AUTOSAR XML (schema 4-2-2)
package /STELLANTIS/EPT/ASWCs
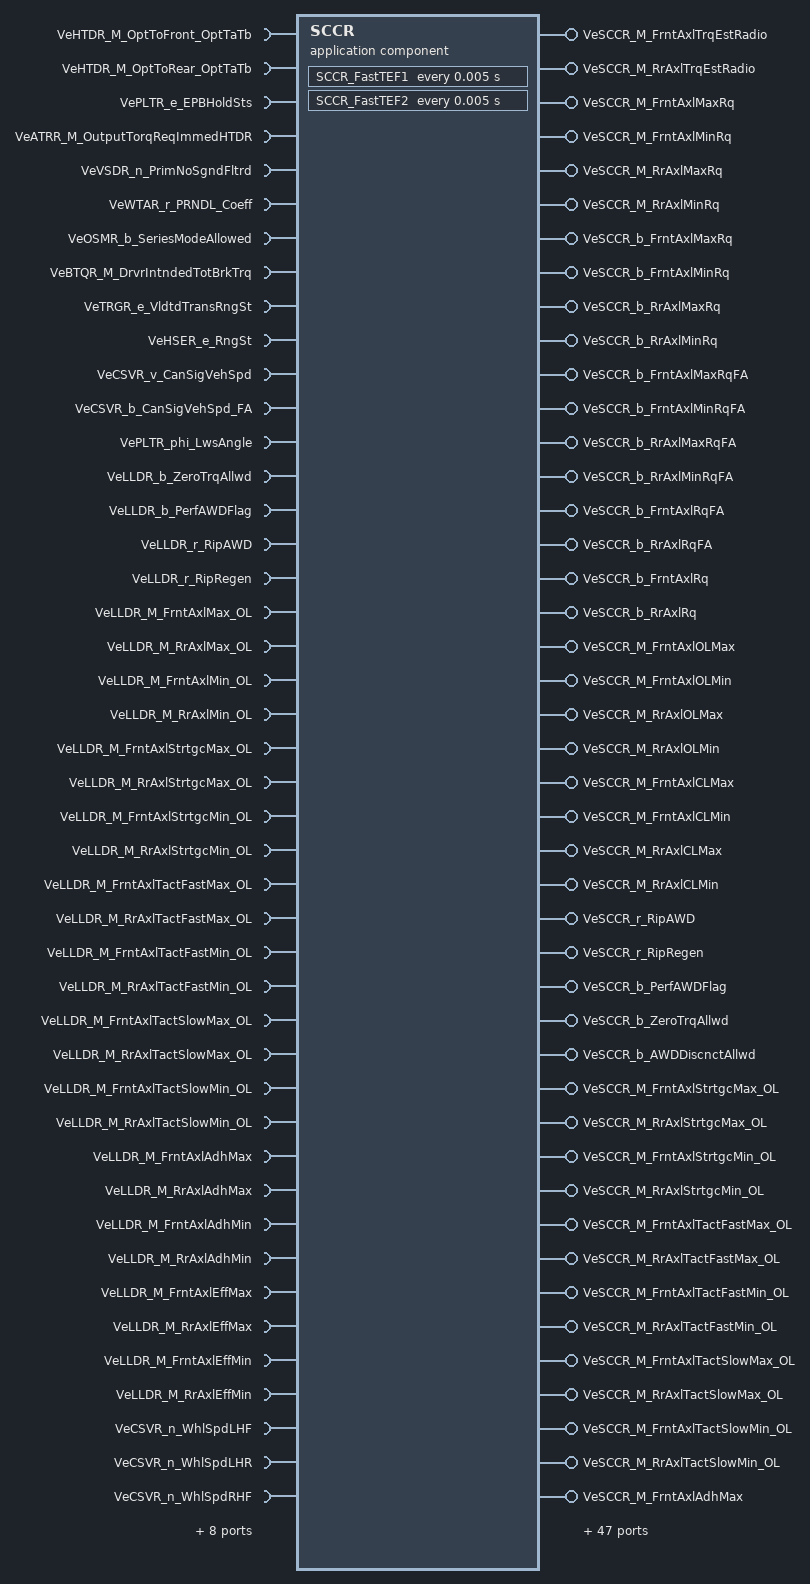
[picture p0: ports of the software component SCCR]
  application sw component type SCCR
    52 x require port:
      VeHTDR_M_OptToFront_OptTaTb: variation-point={short-label=vpVeHTDR_M_OptToFront_OptTaTb, sw-syscond=1}, nonqueued-receiver-com-spec{data-element=Value, init-value=0}, required-interface=VeHTDR_M_OptToFront_OptTaTb
      VeHTDR_M_OptToRear_OptTaTb: variation-point={short-label=vpVeHTDR_M_OptToRear_OptTaTb, sw-syscond=1}, nonqueued-receiver-com-spec{data-element=Value, init-value=0}, required-interface=VeHTDR_M_OptToRear_OptTaTb
      VePLTR_e_EPBHoldSts: variation-point={short-label=vpVePLTR_e_EPBHoldSts, sw-syscond=1}, nonqueued-receiver-com-spec{data-element=Value, init-value=CePLTR_e_EPBHoldSts_REL}, required-interface=VePLTR_e_EPBHoldSts
      VeATRR_M_OutputTorqReqImmedHTDR: variation-point={short-label=vpVeATRR_M_OutputTorqReqImmedHTDR, sw-syscond=1}, nonqueued-receiver-com-spec{data-element=Value, init-value=0}, required-interface=VeATRR_M_OutputTorqReqImmedHTDR
      VeVSDR_n_PrimNoSgndFltrd: variation-point={short-label=vpVeVSDR_n_PrimNoSgndFltrd, sw-syscond=1}, nonqueued-receiver-com-spec{data-element=Value, init-value=0}, required-interface=VeVSDR_n_PrimNoSgndFltrd
      VeWTAR_r_PRNDL_Coeff: variation-point={short-label=vpVeWTAR_r_PRNDL_Coeff, sw-syscond=1}, nonqueued-receiver-com-spec{data-element=Value, init-value=0}, required-interface=VeWTAR_r_PRNDL_Coeff
      VeOSMR_b_SeriesModeAllowed: variation-point={short-label=vpVeOSMR_b_SeriesModeAllowed, sw-syscond=1}, nonqueued-receiver-com-spec{data-element=Value, init-value=0}, required-interface=VeOSMR_b_SeriesModeAllowed
      VeBTQR_M_DrvrIntndedTotBrkTrq: variation-point={short-label=vpVeBTQR_M_DrvrIntndedTotBrkTrq, sw-syscond=1}, nonqueued-receiver-com-spec{data-element=Value, init-value=0}, required-interface=VeBTQR_M_DrvrIntndedTotBrkTrq
      VeTRGR_e_VldtdTransRngSt: variation-point={short-label=vpVeTRGR_e_VldtdTransRngSt, sw-syscond=1}, nonqueued-receiver-com-spec{data-element=Value, init-value=CeTRGR_e_NoSelectionAvailable}, required-interface=VeTRGR_e_VldtdTransRngSt
      VeHSER_e_RngSt: variation-point={short-label=vpVeHSER_e_RngSt, sw-syscond=1}, nonqueued-receiver-com-spec{data-element=Value, init-value=CeHSER_e_Init}, required-interface=VeHSER_e_RngSt
      VeCSVR_v_CanSigVehSpd: variation-point={short-label=vpVeCSVR_v_CanSigVehSpd, sw-syscond=1}, nonqueued-receiver-com-spec{data-element=Value, init-value=0}, required-interface=VeCSVR_v_CanSigVehSpd
      VeCSVR_b_CanSigVehSpd_FA: variation-point={short-label=vpVeCSVR_b_CanSigVehSpd_FA, sw-syscond=1}, nonqueued-receiver-com-spec{data-element=Value, init-value=0}, required-interface=VeCSVR_b_CanSigVehSpd_FA
      VePLTR_phi_LwsAngle: variation-point={short-label=vpVePLTR_phi_LwsAngle, sw-syscond=1}, nonqueued-receiver-com-spec{data-element=Value, init-value=0}, required-interface=VePLTR_phi_LwsAngle
      VeLLDR_b_ZeroTrqAllwd: variation-point={short-label=vpVeLLDR_b_ZeroTrqAllwd, sw-syscond=1}, nonqueued-receiver-com-spec{data-element=Value, init-value=0}, required-interface=VeLLDR_b_ZeroTrqAllwd
      VeLLDR_b_PerfAWDFlag: variation-point={short-label=vpVeLLDR_b_PerfAWDFlag, sw-syscond=1}, nonqueued-receiver-com-spec{data-element=Value, init-value=0}, required-interface=VeLLDR_b_PerfAWDFlag
      VeLLDR_r_RipAWD: variation-point={short-label=vpVeLLDR_r_RipAWD, sw-syscond=1}, nonqueued-receiver-com-spec{data-element=Value, init-value=0}, required-interface=VeLLDR_r_RipAWD
      VeLLDR_r_RipRegen: variation-point={short-label=vpVeLLDR_r_RipRegen, sw-syscond=1}, nonqueued-receiver-com-spec{data-element=Value, init-value=0}, required-interface=VeLLDR_r_RipRegen
      VeLLDR_M_FrntAxlMax_OL: variation-point={short-label=vpVeLLDR_M_FrntAxlMax_OL, sw-syscond=1}, nonqueued-receiver-com-spec{data-element=Value, init-value=0}, required-interface=VeLLDR_M_FrntAxlMax_OL
      VeLLDR_M_RrAxlMax_OL: variation-point={short-label=vpVeLLDR_M_RrAxlMax_OL, sw-syscond=1}, nonqueued-receiver-com-spec{data-element=Value, init-value=0}, required-interface=VeLLDR_M_RrAxlMax_OL
      VeLLDR_M_FrntAxlMin_OL: variation-point={short-label=vpVeLLDR_M_FrntAxlMin_OL, sw-syscond=1}, nonqueued-receiver-com-spec{data-element=Value, init-value=0}, required-interface=VeLLDR_M_FrntAxlMin_OL
      VeLLDR_M_RrAxlMin_OL: variation-point={short-label=vpVeLLDR_M_RrAxlMin_OL, sw-syscond=1}, nonqueued-receiver-com-spec{data-element=Value, init-value=0}, required-interface=VeLLDR_M_RrAxlMin_OL
      VeLLDR_M_FrntAxlStrtgcMax_OL: variation-point={short-label=vpVeLLDR_M_FrntAxlStrtgcMax_OL, sw-syscond=1}, nonqueued-receiver-com-spec{data-element=Value, init-value=0}, required-interface=VeLLDR_M_FrntAxlStrtgcMax_OL
      VeLLDR_M_RrAxlStrtgcMax_OL: variation-point={short-label=vpVeLLDR_M_RrAxlStrtgcMax_OL, sw-syscond=1}, nonqueued-receiver-com-spec{data-element=Value, init-value=0}, required-interface=VeLLDR_M_RrAxlStrtgcMax_OL
      VeLLDR_M_FrntAxlStrtgcMin_OL: variation-point={short-label=vpVeLLDR_M_FrntAxlStrtgcMin_OL, sw-syscond=1}, nonqueued-receiver-com-spec{data-element=Value, init-value=0}, required-interface=VeLLDR_M_FrntAxlStrtgcMin_OL
      VeLLDR_M_RrAxlStrtgcMin_OL: variation-point={short-label=vpVeLLDR_M_RrAxlStrtgcMin_OL, sw-syscond=1}, nonqueued-receiver-com-spec{data-element=Value, init-value=0}, required-interface=VeLLDR_M_RrAxlStrtgcMin_OL
      VeLLDR_M_FrntAxlTactFastMax_OL: variation-point={short-label=vpVeLLDR_M_FrntAxlTactFastMax_OL, sw-syscond=1}, nonqueued-receiver-com-spec{data-element=Value, init-value=0}, required-interface=VeLLDR_M_FrntAxlTactFastMax_OL
      VeLLDR_M_RrAxlTactFastMax_OL: variation-point={short-label=vpVeLLDR_M_RrAxlTactFastMax_OL, sw-syscond=1}, nonqueued-receiver-com-spec{data-element=Value, init-value=0}, required-interface=VeLLDR_M_RrAxlTactFastMax_OL
      VeLLDR_M_FrntAxlTactFastMin_OL: variation-point={short-label=vpVeLLDR_M_FrntAxlTactFastMin_OL, sw-syscond=1}, nonqueued-receiver-com-spec{data-element=Value, init-value=0}, required-interface=VeLLDR_M_FrntAxlTactFastMin_OL
      VeLLDR_M_RrAxlTactFastMin_OL: variation-point={short-label=vpVeLLDR_M_RrAxlTactFastMin_OL, sw-syscond=1}, nonqueued-receiver-com-spec{data-element=Value, init-value=0}, required-interface=VeLLDR_M_RrAxlTactFastMin_OL
      VeLLDR_M_FrntAxlTactSlowMax_OL: variation-point={short-label=vpVeLLDR_M_FrntAxlTactSlowMax_OL, sw-syscond=1}, nonqueued-receiver-com-spec{data-element=Value, init-value=0}, required-interface=VeLLDR_M_FrntAxlTactSlowMax_OL
      VeLLDR_M_RrAxlTactSlowMax_OL: variation-point={short-label=vpVeLLDR_M_RrAxlTactSlowMax_OL, sw-syscond=1}, nonqueued-receiver-com-spec{data-element=Value, init-value=0}, required-interface=VeLLDR_M_RrAxlTactSlowMax_OL
      VeLLDR_M_FrntAxlTactSlowMin_OL: variation-point={short-label=vpVeLLDR_M_FrntAxlTactSlowMin_OL, sw-syscond=1}, nonqueued-receiver-com-spec{data-element=Value, init-value=0}, required-interface=VeLLDR_M_FrntAxlTactSlowMin_OL
      VeLLDR_M_RrAxlTactSlowMin_OL: variation-point={short-label=vpVeLLDR_M_RrAxlTactSlowMin_OL, sw-syscond=1}, nonqueued-receiver-com-spec{data-element=Value, init-value=0}, required-interface=VeLLDR_M_RrAxlTactSlowMin_OL
      VeLLDR_M_FrntAxlAdhMax: variation-point={short-label=vpVeLLDR_M_FrntAxlAdhMax, sw-syscond=1}, nonqueued-receiver-com-spec{data-element=Value, init-value=0}, required-interface=VeLLDR_M_FrntAxlAdhMax
      VeLLDR_M_RrAxlAdhMax: variation-point={short-label=vpVeLLDR_M_RrAxlAdhMax, sw-syscond=1}, nonqueued-receiver-com-spec{data-element=Value, init-value=0}, required-interface=VeLLDR_M_RrAxlAdhMax
      VeLLDR_M_FrntAxlAdhMin: variation-point={short-label=vpVeLLDR_M_FrntAxlAdhMin, sw-syscond=1}, nonqueued-receiver-com-spec{data-element=Value, init-value=0}, required-interface=VeLLDR_M_FrntAxlAdhMin
      VeLLDR_M_RrAxlAdhMin: variation-point={short-label=vpVeLLDR_M_RrAxlAdhMin, sw-syscond=1}, nonqueued-receiver-com-spec{data-element=Value, init-value=0}, required-interface=VeLLDR_M_RrAxlAdhMin
      VeLLDR_M_FrntAxlEffMax: variation-point={short-label=vpVeLLDR_M_FrntAxlEffMax, sw-syscond=1}, nonqueued-receiver-com-spec{data-element=Value, init-value=0}, required-interface=VeLLDR_M_FrntAxlEffMax
      VeLLDR_M_RrAxlEffMax: variation-point={short-label=vpVeLLDR_M_RrAxlEffMax, sw-syscond=1}, nonqueued-receiver-com-spec{data-element=Value, init-value=0}, required-interface=VeLLDR_M_RrAxlEffMax
      VeLLDR_M_FrntAxlEffMin: variation-point={short-label=vpVeLLDR_M_FrntAxlEffMin, sw-syscond=1}, nonqueued-receiver-com-spec{data-element=Value, init-value=0}, required-interface=VeLLDR_M_FrntAxlEffMin
      VeLLDR_M_RrAxlEffMin: variation-point={short-label=vpVeLLDR_M_RrAxlEffMin, sw-syscond=1}, nonqueued-receiver-com-spec{data-element=Value, init-value=0}, required-interface=VeLLDR_M_RrAxlEffMin
      VeCSVR_n_WhlSpdLHF: variation-point={short-label=vpVeCSVR_n_WhlSpdLHF, sw-syscond=1}, nonqueued-receiver-com-spec{data-element=Value, init-value=0}, required-interface=VeCSVR_n_WhlSpdLHF
      VeCSVR_n_WhlSpdLHR: variation-point={short-label=vpVeCSVR_n_WhlSpdLHR, sw-syscond=1}, nonqueued-receiver-com-spec{data-element=Value, init-value=0}, required-interface=VeCSVR_n_WhlSpdLHR
      VeCSVR_n_WhlSpdRHF: variation-point={short-label=vpVeCSVR_n_WhlSpdRHF, sw-syscond=1}, nonqueued-receiver-com-spec{data-element=Value, init-value=0}, required-interface=VeCSVR_n_WhlSpdRHF
      VeCSVR_n_WhlSpdRHR: variation-point={short-label=vpVeCSVR_n_WhlSpdRHR, sw-syscond=1}, nonqueued-receiver-com-spec{data-element=Value, init-value=0}, required-interface=VeCSVR_n_WhlSpdRHR
      VeCSVR_b_WhlSpdLHF_FA: variation-point={short-label=vpVeCSVR_b_WhlSpdLHF_FA, sw-syscond=1}, nonqueued-receiver-com-spec{data-element=Value, init-value=0}, required-interface=VeCSVR_b_WhlSpdLHF_FA
      VeCSVR_b_WhlSpdLHR_FA: variation-point={short-label=vpVeCSVR_b_WhlSpdLHR_FA, sw-syscond=1}, nonqueued-receiver-com-spec{data-element=Value, init-value=0}, required-interface=VeCSVR_b_WhlSpdLHR_FA
      VeCSVR_b_WhlSpdRHF_FA: variation-point={short-label=vpVeCSVR_b_WhlSpdRHF_FA, sw-syscond=1}, nonqueued-receiver-com-spec{data-element=Value, init-value=0}, required-interface=VeCSVR_b_WhlSpdRHF_FA
      VeCSVR_b_WhlSpdRHR_FA: variation-point={short-label=vpVeCSVR_b_WhlSpdRHR_FA, sw-syscond=1}, nonqueued-receiver-com-spec{data-element=Value, init-value=0}, required-interface=VeCSVR_b_WhlSpdRHR_FA
      VeFWDR_M_FricTrqClutch: variation-point={short-label=vpVeFWDR_M_FricTrqClutch, sw-syscond=1}, nonqueued-receiver-com-spec{data-element=Value, init-value=0}, required-interface=VeFWDR_M_FricTrqClutch
      VeAXLR_M_OutTorqReqModHH_Axle: variation-point={short-label=vpVeAXLR_M_OutTorqReqModHH_Axle, sw-syscond=1}, nonqueued-receiver-com-spec{data-element=Value, init-value=0}, required-interface=VeAXLR_M_OutTorqReqModHH_Axle
      VeSRAR_e_LoCHCP_BSM_CANC: variation-point={short-label=vpVeSRAR_e_LoCHCP_BSM_CANC, sw-syscond=1}, nonqueued-receiver-com-spec{data-element=Value, init-value=CeSRAR_e_NoFaultHCPBSM_C1}, required-interface=VeSRAR_e_LoCHCP_BSM_CANC
    91 x provide port:
      VeSCCR_M_FrntAxlTrqEstRadio: nonqueued-sender-com-spec{data-element=Value, init-value=0}, provided-interface=VeSCCR_M_FrntAxlTrqEstRadio
      VeSCCR_M_RrAxlTrqEstRadio: nonqueued-sender-com-spec{data-element=Value, init-value=0}, provided-interface=VeSCCR_M_RrAxlTrqEstRadio
      VeSCCR_M_FrntAxlMaxRq: nonqueued-sender-com-spec{data-element=Value, init-value=0}, provided-interface=VeSCCR_M_FrntAxlMaxRq
      VeSCCR_M_FrntAxlMinRq: nonqueued-sender-com-spec{data-element=Value, init-value=0}, provided-interface=VeSCCR_M_FrntAxlMinRq
      VeSCCR_M_RrAxlMaxRq: nonqueued-sender-com-spec{data-element=Value, init-value=0}, provided-interface=VeSCCR_M_RrAxlMaxRq
      VeSCCR_M_RrAxlMinRq: nonqueued-sender-com-spec{data-element=Value, init-value=0}, provided-interface=VeSCCR_M_RrAxlMinRq
      VeSCCR_b_FrntAxlMaxRq: nonqueued-sender-com-spec{data-element=Value, init-value=0}, provided-interface=VeSCCR_b_FrntAxlMaxRq
      VeSCCR_b_FrntAxlMinRq: nonqueued-sender-com-spec{data-element=Value, init-value=0}, provided-interface=VeSCCR_b_FrntAxlMinRq
      VeSCCR_b_RrAxlMaxRq: nonqueued-sender-com-spec{data-element=Value, init-value=0}, provided-interface=VeSCCR_b_RrAxlMaxRq
      VeSCCR_b_RrAxlMinRq: nonqueued-sender-com-spec{data-element=Value, init-value=0}, provided-interface=VeSCCR_b_RrAxlMinRq
      VeSCCR_b_FrntAxlMaxRqFA: nonqueued-sender-com-spec{data-element=Value, init-value=0}, provided-interface=VeSCCR_b_FrntAxlMaxRqFA
      VeSCCR_b_FrntAxlMinRqFA: nonqueued-sender-com-spec{data-element=Value, init-value=0}, provided-interface=VeSCCR_b_FrntAxlMinRqFA
      VeSCCR_b_RrAxlMaxRqFA: nonqueued-sender-com-spec{data-element=Value, init-value=0}, provided-interface=VeSCCR_b_RrAxlMaxRqFA
      VeSCCR_b_RrAxlMinRqFA: nonqueued-sender-com-spec{data-element=Value, init-value=0}, provided-interface=VeSCCR_b_RrAxlMinRqFA
      VeSCCR_b_FrntAxlRqFA: nonqueued-sender-com-spec{data-element=Value, init-value=0}, provided-interface=VeSCCR_b_FrntAxlRqFA
      VeSCCR_b_RrAxlRqFA: nonqueued-sender-com-spec{data-element=Value, init-value=0}, provided-interface=VeSCCR_b_RrAxlRqFA
      VeSCCR_b_FrntAxlRq: nonqueued-sender-com-spec{data-element=Value, init-value=0}, provided-interface=VeSCCR_b_FrntAxlRq
      VeSCCR_b_RrAxlRq: nonqueued-sender-com-spec{data-element=Value, init-value=0}, provided-interface=VeSCCR_b_RrAxlRq
      VeSCCR_M_FrntAxlOLMax: nonqueued-sender-com-spec{data-element=Value, init-value=0}, provided-interface=VeSCCR_M_FrntAxlOLMax
      VeSCCR_M_FrntAxlOLMin: nonqueued-sender-com-spec{data-element=Value, init-value=0}, provided-interface=VeSCCR_M_FrntAxlOLMin
      VeSCCR_M_RrAxlOLMax: nonqueued-sender-com-spec{data-element=Value, init-value=0}, provided-interface=VeSCCR_M_RrAxlOLMax
      VeSCCR_M_RrAxlOLMin: nonqueued-sender-com-spec{data-element=Value, init-value=0}, provided-interface=VeSCCR_M_RrAxlOLMin
      VeSCCR_M_FrntAxlCLMax: nonqueued-sender-com-spec{data-element=Value, init-value=0}, provided-interface=VeSCCR_M_FrntAxlCLMax
      VeSCCR_M_FrntAxlCLMin: nonqueued-sender-com-spec{data-element=Value, init-value=0}, provided-interface=VeSCCR_M_FrntAxlCLMin
      VeSCCR_M_RrAxlCLMax: nonqueued-sender-com-spec{data-element=Value, init-value=0}, provided-interface=VeSCCR_M_RrAxlCLMax
      VeSCCR_M_RrAxlCLMin: nonqueued-sender-com-spec{data-element=Value, init-value=0}, provided-interface=VeSCCR_M_RrAxlCLMin
      VeSCCR_r_RipAWD: nonqueued-sender-com-spec{data-element=Value, init-value=0}, provided-interface=VeSCCR_r_RipAWD
      VeSCCR_r_RipRegen: nonqueued-sender-com-spec{data-element=Value, init-value=0}, provided-interface=VeSCCR_r_RipRegen
      VeSCCR_b_PerfAWDFlag: nonqueued-sender-com-spec{data-element=Value, init-value=0}, provided-interface=VeSCCR_b_PerfAWDFlag
      VeSCCR_b_ZeroTrqAllwd: nonqueued-sender-com-spec{data-element=Value, init-value=0}, provided-interface=VeSCCR_b_ZeroTrqAllwd
      VeSCCR_b_AWDDiscnctAllwd: nonqueued-sender-com-spec{data-element=Value, init-value=0}, provided-interface=VeSCCR_b_AWDDiscnctAllwd
      VeSCCR_M_FrntAxlStrtgcMax_OL: nonqueued-sender-com-spec{data-element=Value, init-value=0}, provided-interface=VeSCCR_M_FrntAxlStrtgcMax_OL
      VeSCCR_M_RrAxlStrtgcMax_OL: nonqueued-sender-com-spec{data-element=Value, init-value=0}, provided-interface=VeSCCR_M_RrAxlStrtgcMax_OL
      VeSCCR_M_FrntAxlStrtgcMin_OL: nonqueued-sender-com-spec{data-element=Value, init-value=0}, provided-interface=VeSCCR_M_FrntAxlStrtgcMin_OL
      VeSCCR_M_RrAxlStrtgcMin_OL: nonqueued-sender-com-spec{data-element=Value, init-value=0}, provided-interface=VeSCCR_M_RrAxlStrtgcMin_OL
      VeSCCR_M_FrntAxlTactFastMax_OL: nonqueued-sender-com-spec{data-element=Value, init-value=0}, provided-interface=VeSCCR_M_FrntAxlTactFastMax_OL
      VeSCCR_M_RrAxlTactFastMax_OL: nonqueued-sender-com-spec{data-element=Value, init-value=0}, provided-interface=VeSCCR_M_RrAxlTactFastMax_OL
      VeSCCR_M_FrntAxlTactFastMin_OL: nonqueued-sender-com-spec{data-element=Value, init-value=0}, provided-interface=VeSCCR_M_FrntAxlTactFastMin_OL
      VeSCCR_M_RrAxlTactFastMin_OL: nonqueued-sender-com-spec{data-element=Value, init-value=0}, provided-interface=VeSCCR_M_RrAxlTactFastMin_OL
      VeSCCR_M_FrntAxlTactSlowMax_OL: nonqueued-sender-com-spec{data-element=Value, init-value=0}, provided-interface=VeSCCR_M_FrntAxlTactSlowMax_OL
      VeSCCR_M_RrAxlTactSlowMax_OL: nonqueued-sender-com-spec{data-element=Value, init-value=0}, provided-interface=VeSCCR_M_RrAxlTactSlowMax_OL
      VeSCCR_M_FrntAxlTactSlowMin_OL: nonqueued-sender-com-spec{data-element=Value, init-value=0}, provided-interface=VeSCCR_M_FrntAxlTactSlowMin_OL
      VeSCCR_M_RrAxlTactSlowMin_OL: nonqueued-sender-com-spec{data-element=Value, init-value=0}, provided-interface=VeSCCR_M_RrAxlTactSlowMin_OL
      VeSCCR_M_FrntAxlAdhMax: nonqueued-sender-com-spec{data-element=Value, init-value=0}, provided-interface=VeSCCR_M_FrntAxlAdhMax
      VeSCCR_M_RrAxlAdhMax: nonqueued-sender-com-spec{data-element=Value, init-value=0}, provided-interface=VeSCCR_M_RrAxlAdhMax
      VeSCCR_M_FrntAxlAdhMin: nonqueued-sender-com-spec{data-element=Value, init-value=0}, provided-interface=VeSCCR_M_FrntAxlAdhMin
      VeSCCR_M_RrAxlAdhMin: nonqueued-sender-com-spec{data-element=Value, init-value=0}, provided-interface=VeSCCR_M_RrAxlAdhMin
      VeSCCR_M_FrntAxlEffMax: nonqueued-sender-com-spec{data-element=Value, init-value=0}, provided-interface=VeSCCR_M_FrntAxlEffMax
      VeSCCR_M_RrAxlEffMax: nonqueued-sender-com-spec{data-element=Value, init-value=0}, provided-interface=VeSCCR_M_RrAxlEffMax
      VeSCCR_M_FrntAxlEffMin: nonqueued-sender-com-spec{data-element=Value, init-value=0}, provided-interface=VeSCCR_M_FrntAxlEffMin
      VeSCCR_M_RrAxlEffMin: nonqueued-sender-com-spec{data-element=Value, init-value=0}, provided-interface=VeSCCR_M_RrAxlEffMin
      VeSCCR_M_FrntAxlMaxRqPrtctd: nonqueued-sender-com-spec{data-element=Value, init-value=0}, provided-interface=VeSCCR_M_FrntAxlMaxRqPrtctd
      VeSCCR_M_FrntAxlMinRqPrtctd: nonqueued-sender-com-spec{data-element=Value, init-value=0}, provided-interface=VeSCCR_M_FrntAxlMinRqPrtctd
      VeSCCR_b_FrontDFOffReq: nonqueued-sender-com-spec{data-element=Value, init-value=0}, provided-interface=VeSCCR_b_FrontDFOffReq
      VeSCCR_b_RearDFOffReq: nonqueued-sender-com-spec{data-element=Value, init-value=0}, provided-interface=VeSCCR_b_RearDFOffReq
      VeSCCR_M_OutputTorqueLimit: nonqueued-sender-com-spec{data-element=Value, init-value=0}, provided-interface=VeSCCR_M_OutputTorqueLimit
      VeSCCR_b_OutputTorqueLimit_CAN_FA: variation-point={short-label=vpVeSCCR_b_OutputTorqueLimit_CAN_FA, sw-syscond=1}, nonqueued-sender-com-spec{data-element=Value, init-value=0}, provided-interface=VeSCCR_b_OutputTorqueLimit_CAN_FA
      VeSCCR_b_Rq_ESCSum: nonqueued-sender-com-spec{data-element=Value, init-value=0}, provided-interface=VeSCCR_b_Rq_ESCSum
      VeSCCR_M_ESCSumMax: nonqueued-sender-com-spec{data-element=Value, init-value=0}, provided-interface=VeSCCR_M_ESCSumMax
      VeSCCR_M_ESCSumMin: nonqueued-sender-com-spec{data-element=Value, init-value=0}, provided-interface=VeSCCR_M_ESCSumMin
      VeSCCR_b_ESCTrqEnblRq_Allowed: nonqueued-sender-com-spec{data-element=Value, init-value=0}, provided-interface=VeSCCR_b_ESCTrqEnblRq_Allowed
      VeSCCR_b_Rq_ESCSumFA: nonqueued-sender-com-spec{data-element=Value, init-value=0}, provided-interface=VeSCCR_b_Rq_ESCSumFA
      FsftSCCR_M_FlyWRq: server-com-spec=FsftSCCR_M_FlyWRq, provided-interface=FsftSCCR_M_FlyWRq
      FsftSCCR_M_FrntAxlRq: server-com-spec=FsftSCCR_M_FrntAxlRq, provided-interface=FsftSCCR_M_FrntAxlRq
      FsftSCCR_M_Output_Torque_Limit: server-com-spec=FsftSCCR_M_Output_Torque_Limit, provided-interface=FsftSCCR_M_Output_Torque_Limit
      FsftSCCR_M_RrAxlRq: server-com-spec=FsftSCCR_M_RrAxlRq, provided-interface=FsftSCCR_M_RrAxlRq
      FsftSCCR_b_FlyWMaxRq: server-com-spec=FsftSCCR_b_FlyWMaxRq, provided-interface=FsftSCCR_b_FlyWMaxRq
      FsftSCCR_b_FlyWMinRq: server-com-spec=FsftSCCR_b_FlyWMinRq, provided-interface=FsftSCCR_b_FlyWMinRq
      FsftSCCR_b_FrntAxlMaxRq: server-com-spec=FsftSCCR_b_FrntAxlMaxRq, provided-interface=FsftSCCR_b_FrntAxlMaxRq
      FsftSCCR_b_FrntAxlMinRq: server-com-spec=FsftSCCR_b_FrntAxlMinRq, provided-interface=FsftSCCR_b_FrntAxlMinRq
      FsftSCCR_b_RrAxlMaxRq: server-com-spec=FsftSCCR_b_RrAxlMaxRq, provided-interface=FsftSCCR_b_RrAxlMaxRq
      FsftSCCR_b_RrAxlMinRq: server-com-spec=FsftSCCR_b_RrAxlMinRq, provided-interface=FsftSCCR_b_RrAxlMinRq
      PokeSCCR_M_FlyWRq: server-com-spec{operation=PokeSCCR_M_FlyWRq, queue-length=1}, provided-interface=PokeSCCR_M_FlyWRq
      PokeSCCR_M_FrntAxlMax_CL: server-com-spec{operation=PokeSCCR_M_FrntAxlMax_CL, queue-length=1}, provided-interface=PokeSCCR_M_FrntAxlMax_CL
      PokeSCCR_M_FrntAxlMin_CL: server-com-spec{operation=PokeSCCR_M_FrntAxlMin_CL, queue-length=1}, provided-interface=PokeSCCR_M_FrntAxlMin_CL
      PokeSCCR_M_FrntAxlRq: server-com-spec{operation=PokeSCCR_M_FrntAxlRq, queue-length=1}, provided-interface=PokeSCCR_M_FrntAxlRq
      PokeSCCR_M_Output_Torque_Limit: server-com-spec{operation=PokeSCCR_M_Output_Torque_Limit, queue-length=1}, provided-interface=PokeSCCR_M_Output_Torque_Limit
      PokeSCCR_M_RrAxlMax_CL: server-com-spec{operation=PokeSCCR_M_RrAxlMax_CL, queue-length=1}, provided-interface=PokeSCCR_M_RrAxlMax_CL
      PokeSCCR_M_RrAxlMin_CL: server-com-spec{operation=PokeSCCR_M_RrAxlMin_CL, queue-length=1}, provided-interface=PokeSCCR_M_RrAxlMin_CL
      PokeSCCR_M_RrAxlRq: server-com-spec{operation=PokeSCCR_M_RrAxlRq, queue-length=1}, provided-interface=PokeSCCR_M_RrAxlRq
      PokeSCCR_b_AWDDiscnctAllwd: server-com-spec{operation=PokeSCCR_b_AWDDiscnctAllwd, queue-length=1}, provided-interface=PokeSCCR_b_AWDDiscnctAllwd
      PokeSCCR_b_DsblAEMDPGainFrnt: server-com-spec{operation=PokeSCCR_b_DsblAEMDPGainFrnt, queue-length=1}, provided-interface=PokeSCCR_b_DsblAEMDPGainFrnt
      PokeSCCR_b_DsblAEMDPGainRr: server-com-spec{operation=PokeSCCR_b_DsblAEMDPGainRr, queue-length=1}, provided-interface=PokeSCCR_b_DsblAEMDPGainRr
      PokeSCCR_b_FlyWMaxRq: server-com-spec{operation=PokeSCCR_b_FlyWMaxRq, queue-length=1}, provided-interface=PokeSCCR_b_FlyWMaxRq
      PokeSCCR_b_FlyWMinRq: server-com-spec{operation=PokeSCCR_b_FlyWMinRq, queue-length=1}, provided-interface=PokeSCCR_b_FlyWMinRq
      PokeSCCR_b_FrntAxlMaxRq: server-com-spec{operation=PokeSCCR_b_FrntAxlMaxRq, queue-length=1}, provided-interface=PokeSCCR_b_FrntAxlMaxRq
      PokeSCCR_b_FrntAxlMinRq: server-com-spec{operation=PokeSCCR_b_FrntAxlMinRq, queue-length=1}, provided-interface=PokeSCCR_b_FrntAxlMinRq
      PokeSCCR_b_FrontDFOffReq: server-com-spec{operation=PokeSCCR_b_FrontDFOffReq, queue-length=1}, provided-interface=PokeSCCR_b_FrontDFOffReq
      PokeSCCR_b_RearDFOffReq: server-com-spec{operation=PokeSCCR_b_RearDFOffReq, queue-length=1}, provided-interface=PokeSCCR_b_RearDFOffReq
      PokeSCCR_b_RrAxlMaxRq: server-com-spec{operation=PokeSCCR_b_RrAxlMaxRq, queue-length=1}, provided-interface=PokeSCCR_b_RrAxlMaxRq
      PokeSCCR_b_RrAxlMinRq: server-com-spec{operation=PokeSCCR_b_RrAxlMinRq, queue-length=1}, provided-interface=PokeSCCR_b_RrAxlMinRq
    behavior IB_SCCR: data-type-mapping=msADTtoIDTMapping, handle-termination-and-restart=NO-SUPPORT
      timing event Event_FastTEF1: start-on-event=SCCR_FastTEF1, period=0.005
      timing event Event_FastTEF2: start-on-event=SCCR_FastTEF2, period=0.005
      29 x operation invoked event:
        Event_FsftSCCR_M_FlyWRq: start-on-event=FsftSCCR_M_FlyWRq, operation=FsftSCCR_M_FlyWRq.FsftSCCR_M_FlyWRq
        Event_FsftSCCR_M_FrntAxlRq: start-on-event=FsftSCCR_M_FrntAxlRq, operation=FsftSCCR_M_FrntAxlRq.FsftSCCR_M_FrntAxlRq
        Event_FsftSCCR_M_Output_Torque_Limit: start-on-event=FsftSCCR_M_Output_Torque_Limit, operation=FsftSCCR_M_Output_Torque_Limit.FsftSCCR_M_Output_Torque_Limit
        Event_FsftSCCR_M_RrAxlRq: start-on-event=FsftSCCR_M_RrAxlRq, operation=FsftSCCR_M_RrAxlRq.FsftSCCR_M_RrAxlRq
        Event_FsftSCCR_b_FlyWMaxRq: start-on-event=FsftSCCR_b_FlyWMaxRq, operation=FsftSCCR_b_FlyWMaxRq.FsftSCCR_b_FlyWMaxRq
        Event_FsftSCCR_b_FlyWMinRq: start-on-event=FsftSCCR_b_FlyWMinRq, operation=FsftSCCR_b_FlyWMinRq.FsftSCCR_b_FlyWMinRq
        Event_FsftSCCR_b_FrntAxlMaxRq: start-on-event=FsftSCCR_b_FrntAxlMaxRq, operation=FsftSCCR_b_FrntAxlMaxRq.FsftSCCR_b_FrntAxlMaxRq
        Event_FsftSCCR_b_FrntAxlMinRq: start-on-event=FsftSCCR_b_FrntAxlMinRq, operation=FsftSCCR_b_FrntAxlMinRq.FsftSCCR_b_FrntAxlMinRq
        Event_FsftSCCR_b_RrAxlMaxRq: start-on-event=FsftSCCR_b_RrAxlMaxRq, operation=FsftSCCR_b_RrAxlMaxRq.FsftSCCR_b_RrAxlMaxRq
        Event_FsftSCCR_b_RrAxlMinRq: start-on-event=FsftSCCR_b_RrAxlMinRq, operation=FsftSCCR_b_RrAxlMinRq.FsftSCCR_b_RrAxlMinRq
        Event_PokeSCCR_M_FlyWRq: start-on-event=PokeSCCR_M_FlyWRq, operation=PokeSCCR_M_FlyWRq.PokeSCCR_M_FlyWRq
        Event_PokeSCCR_M_FrntAxlMax_CL: start-on-event=PokeSCCR_M_FrntAxlMax_CL, operation=PokeSCCR_M_FrntAxlMax_CL.PokeSCCR_M_FrntAxlMax_CL
        Event_PokeSCCR_M_FrntAxlMin_CL: start-on-event=PokeSCCR_M_FrntAxlMin_CL, operation=PokeSCCR_M_FrntAxlMin_CL.PokeSCCR_M_FrntAxlMin_CL
        Event_PokeSCCR_M_FrntAxlRq: start-on-event=PokeSCCR_M_FrntAxlRq, operation=PokeSCCR_M_FrntAxlRq.PokeSCCR_M_FrntAxlRq
        Event_PokeSCCR_M_Output_Torque_Limit: start-on-event=PokeSCCR_M_Output_Torque_Limit, operation=PokeSCCR_M_Output_Torque_Limit.PokeSCCR_M_Output_Torque_Limit
        Event_PokeSCCR_M_RrAxlMax_CL: start-on-event=PokeSCCR_M_RrAxlMax_CL, operation=PokeSCCR_M_RrAxlMax_CL.PokeSCCR_M_RrAxlMax_CL
        Event_PokeSCCR_M_RrAxlMin_CL: start-on-event=PokeSCCR_M_RrAxlMin_CL, operation=PokeSCCR_M_RrAxlMin_CL.PokeSCCR_M_RrAxlMin_CL
        Event_PokeSCCR_M_RrAxlRq: start-on-event=PokeSCCR_M_RrAxlRq, operation=PokeSCCR_M_RrAxlRq.PokeSCCR_M_RrAxlRq
        Event_PokeSCCR_b_AWDDiscnctAllwd: start-on-event=PokeSCCR_b_AWDDiscnctAllwd, operation=PokeSCCR_b_AWDDiscnctAllwd.PokeSCCR_b_AWDDiscnctAllwd
        Event_PokeSCCR_b_DsblAEMDPGainFrnt: start-on-event=PokeSCCR_b_DsblAEMDPGainFrnt, operation=PokeSCCR_b_DsblAEMDPGainFrnt.PokeSCCR_b_DsblAEMDPGainFrnt
        Event_PokeSCCR_b_DsblAEMDPGainRr: start-on-event=PokeSCCR_b_DsblAEMDPGainRr, operation=PokeSCCR_b_DsblAEMDPGainRr.PokeSCCR_b_DsblAEMDPGainRr
        Event_PokeSCCR_b_FlyWMaxRq: start-on-event=PokeSCCR_b_FlyWMaxRq, operation=PokeSCCR_b_FlyWMaxRq.PokeSCCR_b_FlyWMaxRq
        Event_PokeSCCR_b_FlyWMinRq: start-on-event=PokeSCCR_b_FlyWMinRq, operation=PokeSCCR_b_FlyWMinRq.PokeSCCR_b_FlyWMinRq
        Event_PokeSCCR_b_FrntAxlMaxRq: start-on-event=PokeSCCR_b_FrntAxlMaxRq, operation=PokeSCCR_b_FrntAxlMaxRq.PokeSCCR_b_FrntAxlMaxRq
        Event_PokeSCCR_b_FrntAxlMinRq: start-on-event=PokeSCCR_b_FrntAxlMinRq, operation=PokeSCCR_b_FrntAxlMinRq.PokeSCCR_b_FrntAxlMinRq
        Event_PokeSCCR_b_FrontDFOffReq: start-on-event=PokeSCCR_b_FrontDFOffReq, operation=PokeSCCR_b_FrontDFOffReq.PokeSCCR_b_FrontDFOffReq
        Event_PokeSCCR_b_RearDFOffReq: start-on-event=PokeSCCR_b_RearDFOffReq, operation=PokeSCCR_b_RearDFOffReq.PokeSCCR_b_RearDFOffReq
        Event_PokeSCCR_b_RrAxlMaxRq: start-on-event=PokeSCCR_b_RrAxlMaxRq, operation=PokeSCCR_b_RrAxlMaxRq.PokeSCCR_b_RrAxlMaxRq
        Event_PokeSCCR_b_RrAxlMinRq: start-on-event=PokeSCCR_b_RrAxlMinRq, operation=PokeSCCR_b_RrAxlMinRq.PokeSCCR_b_RrAxlMinRq
      init event Event_SCCR_ac_Init: start-on-event=SCCR_ac_Init
      init event Event_PwrOn: start-on-event=SCCR_PwrOn
      explicit-inter-runnable-variables:
        54 x data, all with category=VALUE, sw-calibration-access=READ-ONLY:
          VeSCCR_b_FrntAxlMaxRq_write_IRV: type=Boolean, init-value=0, variation-point={short-label=vpVeSCCR_b_FrntAxlMaxRq_write_IRV, sw-syscond=1}
          VeSCCR_b_FlyWMaxRq_write_IRV: type=Boolean, init-value=0, variation-point={short-label=vpVeSCCR_b_FlyWMaxRq_write_IRV, sw-syscond=1}
          VeSCCR_b_FrntAxlMinRq_write_IRV: type=Boolean, init-value=0, variation-point={short-label=vpVeSCCR_b_FrntAxlMinRq_write_IRV, sw-syscond=1}
          VeSCCR_b_FlyWMinRq_write_IRV: type=Boolean, init-value=0, variation-point={short-label=vpVeSCCR_b_FlyWMinRq_write_IRV, sw-syscond=1}
          VeSCCR_M_FrntAxlRq_write_IRV: type=Float, init-value=0, variation-point={short-label=vpVeSCCR_M_FrntAxlRq_write_IRV, sw-syscond=1}
          VeSCCR_M_FlyWRq_write_IRV: type=Float, init-value=0, variation-point={short-label=vpVeSCCR_M_FlyWRq_write_IRV, sw-syscond=1}
          VeSCCR_b_RrAxlMaxRq_write_IRV: type=Boolean, init-value=0, variation-point={short-label=vpVeSCCR_b_RrAxlMaxRq_write_IRV, sw-syscond=1}
          VeSCCR_b_RrAxlMinRq_write_IRV: type=Boolean, init-value=0, variation-point={short-label=vpVeSCCR_b_RrAxlMinRq_write_IRV, sw-syscond=1}
          VeSCCR_M_RrAxlRq_write_IRV: type=Float, init-value=0, variation-point={short-label=vpVeSCCR_M_RrAxlRq_write_IRV, sw-syscond=1}
          VeSCCR_b_FrntAxlMaxRqFA_write_IRV: type=Boolean, init-value=0, variation-point={short-label=vpVeSCCR_b_FrntAxlMaxRqFA_write_IRV, sw-syscond=1}
          VeSCCR_b_FlyWMaxRq_FA_write_IRV: type=Boolean, init-value=0, variation-point={short-label=vpVeSCCR_b_FlyWMaxRq_FA_write_IRV, sw-syscond=1}
          VeSCCR_b_FrntAxlMinRqFA_write_IRV: type=Boolean, init-value=0, variation-point={short-label=vpVeSCCR_b_FrntAxlMinRqFA_write_IRV, sw-syscond=1}
          VeSCCR_b_FlyWMinRq_FA_write_IRV: type=Boolean, init-value=0, variation-point={short-label=vpVeSCCR_b_FlyWMinRq_FA_write_IRV, sw-syscond=1}
          VeSCCR_b_FrntAxlRqFA_write_IRV: type=Boolean, init-value=0, variation-point={short-label=vpVeSCCR_b_FrntAxlRqFA_write_IRV, sw-syscond=1}
          VeSCCR_b_FlyWRq_FA_write_IRV: type=Boolean, init-value=0, variation-point={short-label=vpVeSCCR_b_FlyWRq_FA_write_IRV, sw-syscond=1}
          VeSCCR_b_RrAxlMaxRqFA_write_IRV: type=Boolean, init-value=0, variation-point={short-label=vpVeSCCR_b_RrAxlMaxRqFA_write_IRV, sw-syscond=1}
          VeSCCR_b_RrAxlMinRqFA_write_IRV: type=Boolean, init-value=0, variation-point={short-label=vpVeSCCR_b_RrAxlMinRqFA_write_IRV, sw-syscond=1}
          VeSCCR_b_RrAxlRqFA_write_IRV: type=Boolean, init-value=0, variation-point={short-label=vpVeSCCR_b_RrAxlRqFA_write_IRV, sw-syscond=1}
          VeSCCR_M_FrntAxlMax_CL_write_IRV: type=Float, init-value=0
          VeSCCR_M_FrntAxlMin_CL_write_IRV: type=Float, init-value=0
          VeSCCR_M_RrAxlMax_CL_write_IRV: type=Float, init-value=0
          VeSCCR_M_RrAxlMin_CL_write_IRV: type=Float, init-value=0
          VeSCCR_b_AWDDiscnctAllwd_write_IRV: type=Boolean, init-value=0
          VeSCCR_b_DsblAEMDPGainFrnt_write_IRV: type=Boolean, init-value=0
          VeSCCR_b_DsblAEMDPGainRr_write_IRV: type=Boolean, init-value=0
          VeSCCR_b_FrontDFOffReq_write_IRV: type=Boolean, init-value=0
          VeSCCR_b_RearDFOffReq_write_IRV: type=Boolean, init-value=0
          VeSCCI_b_FrntAxlMaxRq_write_IRV: type=Boolean, init-value=0, variation-point={short-label=vpVeSCCI_b_FrntAxlMaxRq_write_IRV, sw-syscond=1}
          VeSCCI_b_FrntAxlMinRq_write_IRV: type=Boolean, init-value=0, variation-point={short-label=vpVeSCCI_b_FrntAxlMinRq_write_IRV, sw-syscond=1}
          VeSCCI_M_FrntAxlRq_write_IRV: type=Float, init-value=0, variation-point={short-label=vpVeSCCI_M_FrntAxlRq_write_IRV, sw-syscond=1}
          VeSCCI_M_RrAxlRq_write_IRV: type=Float, init-value=0, variation-point={short-label=vpVeSCCI_M_RrAxlRq_write_IRV, sw-syscond=1}
          VeSCCI_b_FrntAxlMaxRqFA_write_IRV: type=Boolean, init-value=0
          VeSCCI_b_FrntAxlMinRqFA_write_IRV: type=Boolean, init-value=0
          VeSCCI_b_FrntAxlTqRqFA_write_IRV: type=Boolean, init-value=0, variation-point={short-label=vpVeSCCI_b_FrntAxlTqRqFA_write_IRV, sw-syscond=1}
          VeSCCI_b_RrAxlMaxRq_write_IRV: type=Boolean, init-value=0, variation-point={short-label=vpVeSCCI_b_RrAxlMaxRq_write_IRV, sw-syscond=1}
          VeSCCI_b_RrAxlMaxRqFA_write_IRV: type=Boolean, init-value=0
          VeSCCI_b_RrAxlMinRqFA_write_IRV: type=Boolean, init-value=0
          VeSCCI_b_RrAxlTqRqFA_write_IRV: type=Boolean, init-value=0, variation-point={short-label=vpVeSCCI_b_RrAxlTqRqFA_write_IRV, sw-syscond=1}
          VeSCCI_b_RrAxlMinRq_write_IRV: type=Boolean, init-value=0, variation-point={short-label=vpVeSCCI_b_RrAxlMinRq_write_IRV, sw-syscond=1}
          VeSCCI_e_EPBHoldSts_write_IRV: type=TePLTR_e_EPBHoldSts, init-value=CePLTR_e_EPBHoldSts_REL, variation-point={short-label=vpVeSCCI_e_EPBHoldSts_write_IRV, sw-syscond=1}
          VeSCCI_M_FrntAxlTrqEst_write_IRV: type=Float, init-value=0, variation-point={short-label=vpVeSCCI_M_FrntAxlTrqEst_write_IRV, sw-syscond=1}
          VeSCCI_M_RrAxlTrqEst_write_IRV: type=Float, init-value=0, variation-point={short-label=vpVeSCCI_M_RrAxlTrqEst_write_IRV, sw-syscond=1}
          VeSCCI_M_FrntAxlOLMax_write_IRV: type=Float, init-value=0
          VeSCCI_M_FrntAxlOLMin_write_IRV: type=Float, init-value=0
          VeSCCI_M_RrAxlOLMax_write_IRV: type=Float, init-value=0
          VeSCCI_M_RrAxlOLMin_write_IRV: type=Float, init-value=0
          VeSCCI_M_FrntAxlCLMax_write_IRV: type=Float, init-value=0
          VeSCCI_M_FrntAxlCLMin_write_IRV: type=Float, init-value=0
          VeSCCI_M_RrAxlCLMax_write_IRV: type=Float, init-value=0
          VeSCCI_M_RrAxlCLMin_write_IRV: type=Float, init-value=0
          VeSCCI_b_DsblAEMDPGainFrnt_write_IRV: type=Boolean, init-value=0, variation-point={short-label=vpVeSCCI_b_DsblAEMDPGainFrnt_write_IRV, sw-syscond=1}
          VeSCCI_b_DsblAEMDPGainRr_write_IRV: type=Boolean, init-value=0, variation-point={short-label=vpVeSCCI_b_DsblAEMDPGainRr_write_IRV, sw-syscond=1}
          VeSCCR_M_Output_Torque_Limit_write_IRV: type=Float, init-value=0
          VeSCCR_b_Output_Torque_LimitFA_write_IRV: type=Boolean, init-value=0
      33 x runnable:
        SCCR_ac_Init
          data-send-points:
            62 x access:
              OUT_VeSCCR_M_FrntAxlTrqEstRadio_Value: accessed-variable=VeSCCR_M_FrntAxlTrqEstRadio.Value
              OUT_VeSCCR_M_RrAxlTrqEstRadio_Value: accessed-variable=VeSCCR_M_RrAxlTrqEstRadio.Value
              OUT_VeSCCR_M_FrntAxlMaxRq_Value: accessed-variable=VeSCCR_M_FrntAxlMaxRq.Value
              OUT_VeSCCR_M_FrntAxlMinRq_Value: accessed-variable=VeSCCR_M_FrntAxlMinRq.Value
              OUT_VeSCCR_M_RrAxlMaxRq_Value: accessed-variable=VeSCCR_M_RrAxlMaxRq.Value
              OUT_VeSCCR_M_RrAxlMinRq_Value: accessed-variable=VeSCCR_M_RrAxlMinRq.Value
              OUT_VeSCCR_b_FrntAxlMaxRq_Value: accessed-variable=VeSCCR_b_FrntAxlMaxRq.Value
              OUT_VeSCCR_b_FrntAxlMinRq_Value: accessed-variable=VeSCCR_b_FrntAxlMinRq.Value
              OUT_VeSCCR_b_RrAxlMaxRq_Value: accessed-variable=VeSCCR_b_RrAxlMaxRq.Value
              OUT_VeSCCR_b_RrAxlMinRq_Value: accessed-variable=VeSCCR_b_RrAxlMinRq.Value
              OUT_VeSCCR_b_FrntAxlMaxRqFA_Value: accessed-variable=VeSCCR_b_FrntAxlMaxRqFA.Value
              OUT_VeSCCR_b_FrntAxlMinRqFA_Value: accessed-variable=VeSCCR_b_FrntAxlMinRqFA.Value
              OUT_VeSCCR_b_RrAxlMaxRqFA_Value: accessed-variable=VeSCCR_b_RrAxlMaxRqFA.Value
              OUT_VeSCCR_b_RrAxlMinRqFA_Value: accessed-variable=VeSCCR_b_RrAxlMinRqFA.Value
              OUT_VeSCCR_b_FrntAxlRqFA_Value: accessed-variable=VeSCCR_b_FrntAxlRqFA.Value
              OUT_VeSCCR_b_RrAxlRqFA_Value: accessed-variable=VeSCCR_b_RrAxlRqFA.Value
              OUT_VeSCCR_b_FrntAxlRq_Value: accessed-variable=VeSCCR_b_FrntAxlRq.Value
              OUT_VeSCCR_b_RrAxlRq_Value: accessed-variable=VeSCCR_b_RrAxlRq.Value
              OUT_VeSCCR_M_FrntAxlOLMax_Value: accessed-variable=VeSCCR_M_FrntAxlOLMax.Value
              OUT_VeSCCR_M_FrntAxlOLMin_Value: accessed-variable=VeSCCR_M_FrntAxlOLMin.Value
              OUT_VeSCCR_M_RrAxlOLMax_Value: accessed-variable=VeSCCR_M_RrAxlOLMax.Value
              OUT_VeSCCR_M_RrAxlOLMin_Value: accessed-variable=VeSCCR_M_RrAxlOLMin.Value
              OUT_VeSCCR_M_FrntAxlCLMax_Value: accessed-variable=VeSCCR_M_FrntAxlCLMax.Value
              OUT_VeSCCR_M_FrntAxlCLMin_Value: accessed-variable=VeSCCR_M_FrntAxlCLMin.Value
              OUT_VeSCCR_M_RrAxlCLMax_Value: accessed-variable=VeSCCR_M_RrAxlCLMax.Value
              OUT_VeSCCR_M_RrAxlCLMin_Value: accessed-variable=VeSCCR_M_RrAxlCLMin.Value
              OUT_VeSCCR_r_RipAWD_Value: accessed-variable=VeSCCR_r_RipAWD.Value
              OUT_VeSCCR_r_RipRegen_Value: accessed-variable=VeSCCR_r_RipRegen.Value
              OUT_VeSCCR_b_PerfAWDFlag_Value: accessed-variable=VeSCCR_b_PerfAWDFlag.Value
              OUT_VeSCCR_b_ZeroTrqAllwd_Value: accessed-variable=VeSCCR_b_ZeroTrqAllwd.Value
              OUT_VeSCCR_b_AWDDiscnctAllwd_Value: accessed-variable=VeSCCR_b_AWDDiscnctAllwd.Value
              OUT_VeSCCR_M_FrntAxlStrtgcMax_OL_Value: accessed-variable=VeSCCR_M_FrntAxlStrtgcMax_OL.Value
              OUT_VeSCCR_M_RrAxlStrtgcMax_OL_Value: accessed-variable=VeSCCR_M_RrAxlStrtgcMax_OL.Value
              OUT_VeSCCR_M_FrntAxlStrtgcMin_OL_Value: accessed-variable=VeSCCR_M_FrntAxlStrtgcMin_OL.Value
              OUT_VeSCCR_M_RrAxlStrtgcMin_OL_Value: accessed-variable=VeSCCR_M_RrAxlStrtgcMin_OL.Value
              OUT_VeSCCR_M_FrntAxlTactFastMax_OL_Value: accessed-variable=VeSCCR_M_FrntAxlTactFastMax_OL.Value
              OUT_VeSCCR_M_RrAxlTactFastMax_OL_Value: accessed-variable=VeSCCR_M_RrAxlTactFastMax_OL.Value
              OUT_VeSCCR_M_FrntAxlTactFastMin_OL_Value: accessed-variable=VeSCCR_M_FrntAxlTactFastMin_OL.Value
              OUT_VeSCCR_M_RrAxlTactFastMin_OL_Value: accessed-variable=VeSCCR_M_RrAxlTactFastMin_OL.Value
              OUT_VeSCCR_M_FrntAxlTactSlowMax_OL_Value: accessed-variable=VeSCCR_M_FrntAxlTactSlowMax_OL.Value
              OUT_VeSCCR_M_RrAxlTactSlowMax_OL_Value: accessed-variable=VeSCCR_M_RrAxlTactSlowMax_OL.Value
              OUT_VeSCCR_M_FrntAxlTactSlowMin_OL_Value: accessed-variable=VeSCCR_M_FrntAxlTactSlowMin_OL.Value
              OUT_VeSCCR_M_RrAxlTactSlowMin_OL_Value: accessed-variable=VeSCCR_M_RrAxlTactSlowMin_OL.Value
              OUT_VeSCCR_M_FrntAxlAdhMax_Value: accessed-variable=VeSCCR_M_FrntAxlAdhMax.Value
              OUT_VeSCCR_M_RrAxlAdhMax_Value: accessed-variable=VeSCCR_M_RrAxlAdhMax.Value
              OUT_VeSCCR_M_FrntAxlAdhMin_Value: accessed-variable=VeSCCR_M_FrntAxlAdhMin.Value
              OUT_VeSCCR_M_RrAxlAdhMin_Value: accessed-variable=VeSCCR_M_RrAxlAdhMin.Value
              OUT_VeSCCR_M_FrntAxlEffMax_Value: accessed-variable=VeSCCR_M_FrntAxlEffMax.Value
              OUT_VeSCCR_M_RrAxlEffMax_Value: accessed-variable=VeSCCR_M_RrAxlEffMax.Value
              OUT_VeSCCR_M_FrntAxlEffMin_Value: accessed-variable=VeSCCR_M_FrntAxlEffMin.Value
              OUT_VeSCCR_M_RrAxlEffMin_Value: accessed-variable=VeSCCR_M_RrAxlEffMin.Value
              OUT_VeSCCR_M_FrntAxlMaxRqPrtctd_Value: accessed-variable=VeSCCR_M_FrntAxlMaxRqPrtctd.Value
              OUT_VeSCCR_M_FrntAxlMinRqPrtctd_Value: accessed-variable=VeSCCR_M_FrntAxlMinRqPrtctd.Value
              OUT_VeSCCR_b_FrontDFOffReq_Value: accessed-variable=VeSCCR_b_FrontDFOffReq.Value
              OUT_VeSCCR_b_RearDFOffReq_Value: accessed-variable=VeSCCR_b_RearDFOffReq.Value
              OUT_VeSCCR_M_OutputTorqueLimit_Value: accessed-variable=VeSCCR_M_OutputTorqueLimit.Value
              OUT_VeSCCR_b_Rq_ESCSum_Value: accessed-variable=VeSCCR_b_Rq_ESCSum.Value
              OUT_VeSCCR_M_ESCSumMax_Value: accessed-variable=VeSCCR_M_ESCSumMax.Value
              OUT_VeSCCR_M_ESCSumMin_Value: accessed-variable=VeSCCR_M_ESCSumMin.Value
              OUT_VeSCCR_b_ESCTrqEnblRq_Allowed_Value: accessed-variable=VeSCCR_b_ESCTrqEnblRq_Allowed.Value
              OUT_VeSCCR_b_Rq_ESCSumFA_Value: accessed-variable=VeSCCR_b_Rq_ESCSumFA.Value
              OUT_VeSCCR_b_OutputTorqueLimit_CAN_FA_Value: accessed-variable=VeSCCR_b_OutputTorqueLimit_CAN_FA.Value, variation-point={short-label=vpOUT_VeSCCR_b_OutputTorqueLimit_CAN_FA_Value, sw-syscond=1}
        SCCR_PwrOn
          data-send-points:
            61 x access:
              OUT_VeSCCR_b_FrntAxlMaxRqFA_Value: accessed-variable=VeSCCR_b_FrntAxlMaxRqFA.Value
              OUT_VeSCCR_b_RrAxlMinRqFA_Value: accessed-variable=VeSCCR_b_RrAxlMinRqFA.Value
              OUT_VeSCCR_b_FrntAxlMinRqFA_Value: accessed-variable=VeSCCR_b_FrntAxlMinRqFA.Value
              OUT_VeSCCR_b_ZeroTrqAllwd_Value: accessed-variable=VeSCCR_b_ZeroTrqAllwd.Value
              OUT_VeSCCR_b_AWDDiscnctAllwd_Value: accessed-variable=VeSCCR_b_AWDDiscnctAllwd.Value
              OUT_VeSCCR_M_FrntAxlOLMax_Value: accessed-variable=VeSCCR_M_FrntAxlOLMax.Value
              OUT_VeSCCR_M_FrntAxlOLMin_Value: accessed-variable=VeSCCR_M_FrntAxlOLMin.Value
              OUT_VeSCCR_M_RrAxlOLMax_Value: accessed-variable=VeSCCR_M_RrAxlOLMax.Value
              OUT_VeSCCR_M_RrAxlOLMin_Value: accessed-variable=VeSCCR_M_RrAxlOLMin.Value
              OUT_VeSCCR_M_FrntAxlCLMax_Value: accessed-variable=VeSCCR_M_FrntAxlCLMax.Value
              OUT_VeSCCR_M_FrntAxlCLMin_Value: accessed-variable=VeSCCR_M_FrntAxlCLMin.Value
              OUT_VeSCCR_M_RrAxlCLMax_Value: accessed-variable=VeSCCR_M_RrAxlCLMax.Value
              OUT_VeSCCR_M_RrAxlCLMin_Value: accessed-variable=VeSCCR_M_RrAxlCLMin.Value
              OUT_VeSCCR_r_RipAWD_Value: accessed-variable=VeSCCR_r_RipAWD.Value
              OUT_VeSCCR_r_RipRegen_Value: accessed-variable=VeSCCR_r_RipRegen.Value
              OUT_VeSCCR_b_PerfAWDFlag_Value: accessed-variable=VeSCCR_b_PerfAWDFlag.Value
              OUT_VeSCCR_M_FrntAxlStrtgcMax_OL_Value: accessed-variable=VeSCCR_M_FrntAxlStrtgcMax_OL.Value
              OUT_VeSCCR_M_RrAxlStrtgcMax_OL_Value: accessed-variable=VeSCCR_M_RrAxlStrtgcMax_OL.Value
              OUT_VeSCCR_M_FrntAxlStrtgcMin_OL_Value: accessed-variable=VeSCCR_M_FrntAxlStrtgcMin_OL.Value
              OUT_VeSCCR_M_RrAxlStrtgcMin_OL_Value: accessed-variable=VeSCCR_M_RrAxlStrtgcMin_OL.Value
              OUT_VeSCCR_M_FrntAxlTactFastMax_OL_Value: accessed-variable=VeSCCR_M_FrntAxlTactFastMax_OL.Value
              OUT_VeSCCR_M_RrAxlTactFastMax_OL_Value: accessed-variable=VeSCCR_M_RrAxlTactFastMax_OL.Value
              OUT_VeSCCR_M_FrntAxlTactFastMin_OL_Value: accessed-variable=VeSCCR_M_FrntAxlTactFastMin_OL.Value
              OUT_VeSCCR_M_RrAxlTactFastMin_OL_Value: accessed-variable=VeSCCR_M_RrAxlTactFastMin_OL.Value
              OUT_VeSCCR_M_FrntAxlTactSlowMax_OL_Value: accessed-variable=VeSCCR_M_FrntAxlTactSlowMax_OL.Value
              OUT_VeSCCR_M_RrAxlTactSlowMax_OL_Value: accessed-variable=VeSCCR_M_RrAxlTactSlowMax_OL.Value
              OUT_VeSCCR_M_FrntAxlTactSlowMin_OL_Value: accessed-variable=VeSCCR_M_FrntAxlTactSlowMin_OL.Value
              OUT_VeSCCR_M_RrAxlTactSlowMin_OL_Value: accessed-variable=VeSCCR_M_RrAxlTactSlowMin_OL.Value
              OUT_VeSCCR_M_FrntAxlAdhMax_Value: accessed-variable=VeSCCR_M_FrntAxlAdhMax.Value
              OUT_VeSCCR_M_RrAxlAdhMax_Value: accessed-variable=VeSCCR_M_RrAxlAdhMax.Value
              OUT_VeSCCR_M_FrntAxlAdhMin_Value: accessed-variable=VeSCCR_M_FrntAxlAdhMin.Value
              OUT_VeSCCR_M_RrAxlAdhMin_Value: accessed-variable=VeSCCR_M_RrAxlAdhMin.Value
              OUT_VeSCCR_M_FrntAxlEffMax_Value: accessed-variable=VeSCCR_M_FrntAxlEffMax.Value
              OUT_VeSCCR_M_RrAxlEffMax_Value: accessed-variable=VeSCCR_M_RrAxlEffMax.Value
              OUT_VeSCCR_M_FrntAxlEffMin_Value: accessed-variable=VeSCCR_M_FrntAxlEffMin.Value
              OUT_VeSCCR_M_RrAxlEffMin_Value: accessed-variable=VeSCCR_M_RrAxlEffMin.Value
              OUT_VeSCCR_b_FrontDFOffReq_Value: accessed-variable=VeSCCR_b_FrontDFOffReq.Value
              OUT_VeSCCR_b_RearDFOffReq_Value: accessed-variable=VeSCCR_b_RearDFOffReq.Value
              OUT_VeSCCR_b_RrAxlMaxRqFA_Value: accessed-variable=VeSCCR_b_RrAxlMaxRqFA.Value
              OUT_VeSCCR_M_FrntAxlMaxRqPrtctd_Value: accessed-variable=VeSCCR_M_FrntAxlMaxRqPrtctd.Value
              OUT_VeSCCR_b_FrntAxlMinRq_Value: accessed-variable=VeSCCR_b_FrntAxlMinRq.Value
              OUT_VeSCCR_M_RrAxlTrqEstRadio_Value: accessed-variable=VeSCCR_M_RrAxlTrqEstRadio.Value
              OUT_VeSCCR_M_FrntAxlTrqEstRadio_Value: accessed-variable=VeSCCR_M_FrntAxlTrqEstRadio.Value
              OUT_VeSCCR_b_RrAxlMinRq_Value: accessed-variable=VeSCCR_b_RrAxlMinRq.Value
              OUT_VeSCCR_b_RrAxlMaxRq_Value: accessed-variable=VeSCCR_b_RrAxlMaxRq.Value
              OUT_VeSCCR_b_FrntAxlRqFA_Value: accessed-variable=VeSCCR_b_FrntAxlRqFA.Value
              OUT_VeSCCR_b_RrAxlRqFA_Value: accessed-variable=VeSCCR_b_RrAxlRqFA.Value
              OUT_VeSCCR_b_FrntAxlRq_Value: accessed-variable=VeSCCR_b_FrntAxlRq.Value
              OUT_VeSCCR_b_RrAxlRq_Value: accessed-variable=VeSCCR_b_RrAxlRq.Value
              OUT_VeSCCR_M_FrntAxlMinRqPrtctd_Value: accessed-variable=VeSCCR_M_FrntAxlMinRqPrtctd.Value
              OUT_VeSCCR_M_FrntAxlMaxRq_Value: accessed-variable=VeSCCR_M_FrntAxlMaxRq.Value
              OUT_VeSCCR_M_FrntAxlMinRq_Value: accessed-variable=VeSCCR_M_FrntAxlMinRq.Value
              OUT_VeSCCR_M_RrAxlMaxRq_Value: accessed-variable=VeSCCR_M_RrAxlMaxRq.Value
              OUT_VeSCCR_M_RrAxlMinRq_Value: accessed-variable=VeSCCR_M_RrAxlMinRq.Value
              OUT_VeSCCR_b_FrntAxlMaxRq_Value: accessed-variable=VeSCCR_b_FrntAxlMaxRq.Value
              OUT_VeSCCR_M_OutputTorqueLimit_Value: accessed-variable=VeSCCR_M_OutputTorqueLimit.Value
              OUT_VeSCCR_M_ESCSumMin_Value: accessed-variable=VeSCCR_M_ESCSumMin.Value
              OUT_VeSCCR_M_ESCSumMax_Value: accessed-variable=VeSCCR_M_ESCSumMax.Value
              OUT_VeSCCR_b_Rq_ESCSum_Value: accessed-variable=VeSCCR_b_Rq_ESCSum.Value
              OUT_VeSCCR_b_Rq_ESCSumFA_Value: accessed-variable=VeSCCR_b_Rq_ESCSumFA.Value
              OUT_VeSCCR_b_ESCTrqEnblRq_Allowed_Value: accessed-variable=VeSCCR_b_ESCTrqEnblRq_Allowed.Value
          written-local-variables:
            42 x access:
              WV_VeSCCR_M_FlyWRq_write_IRV: accessed-variable=VeSCCR_M_FlyWRq_write_IRV, variation-point={short-label=vpWV_VeSCCR_M_FlyWRq_write_IRV, sw-syscond=1}
              WV_VeSCCI_M_FrntAxlCLMax_write_IRV: accessed-variable=VeSCCI_M_FrntAxlCLMax_write_IRV
              WV_VeSCCI_M_FrntAxlCLMin_write_IRV: accessed-variable=VeSCCI_M_FrntAxlCLMin_write_IRV
              WV_VeSCCI_M_FrntAxlOLMax_write_IRV: accessed-variable=VeSCCI_M_FrntAxlOLMax_write_IRV
              WV_VeSCCI_M_FrntAxlOLMin_write_IRV: accessed-variable=VeSCCI_M_FrntAxlOLMin_write_IRV
              WV_VeSCCI_M_FrntAxlRq_write_IRV: accessed-variable=VeSCCI_M_FrntAxlRq_write_IRV, variation-point={short-label=vpWV_VeSCCI_M_FrntAxlRq_write_IRV, sw-syscond=1}
              WV_VeSCCI_M_FrntAxlTrqEst_write_IRV: accessed-variable=VeSCCI_M_FrntAxlTrqEst_write_IRV, variation-point={short-label=vpWV_VeSCCI_M_FrntAxlTrqEst_write_IRV, sw-syscond=1}
              WV_VeSCCR_M_Output_Torque_Limit_write_IRV: accessed-variable=VeSCCR_M_Output_Torque_Limit_write_IRV
              WV_VeSCCI_M_RrAxlCLMax_write_IRV: accessed-variable=VeSCCI_M_RrAxlCLMax_write_IRV
              WV_VeSCCI_M_RrAxlCLMin_write_IRV: accessed-variable=VeSCCI_M_RrAxlCLMin_write_IRV
              WV_VeSCCI_M_RrAxlOLMax_write_IRV: accessed-variable=VeSCCI_M_RrAxlOLMax_write_IRV
              WV_VeSCCI_M_RrAxlOLMin_write_IRV: accessed-variable=VeSCCI_M_RrAxlOLMin_write_IRV
              WV_VeSCCI_M_RrAxlRq_write_IRV: accessed-variable=VeSCCI_M_RrAxlRq_write_IRV, variation-point={short-label=vpWV_VeSCCI_M_RrAxlRq_write_IRV, sw-syscond=1}
              WV_VeSCCI_M_RrAxlTrqEst_write_IRV: accessed-variable=VeSCCI_M_RrAxlTrqEst_write_IRV, variation-point={short-label=vpWV_VeSCCI_M_RrAxlTrqEst_write_IRV, sw-syscond=1}
              WV_VeSCCI_b_DsblAEMDPGainFrnt_write_IRV: accessed-variable=VeSCCI_b_DsblAEMDPGainFrnt_write_IRV, variation-point={short-label=vpWV_VeSCCI_b_DsblAEMDPGainFrnt_write_IRV, sw-syscond=1}
              WV_VeSCCI_b_DsblAEMDPGainRr_write_IRV: accessed-variable=VeSCCI_b_DsblAEMDPGainRr_write_IRV, variation-point={short-label=vpWV_VeSCCI_b_DsblAEMDPGainRr_write_IRV, sw-syscond=1}
              WV_VeSCCI_b_FrntAxlMaxRqFA_write_IRV: accessed-variable=VeSCCI_b_FrntAxlMaxRqFA_write_IRV
              WV_VeSCCI_b_FrntAxlMaxRq_write_IRV: accessed-variable=VeSCCI_b_FrntAxlMaxRq_write_IRV, variation-point={short-label=vpWV_VeSCCI_b_FrntAxlMaxRq_write_IRV, sw-syscond=1}
              WV_VeSCCI_b_FrntAxlMinRqFA_write_IRV: accessed-variable=VeSCCI_b_FrntAxlMinRqFA_write_IRV
              WV_VeSCCI_b_FrntAxlMinRq_write_IRV: accessed-variable=VeSCCI_b_FrntAxlMinRq_write_IRV, variation-point={short-label=vpWV_VeSCCI_b_FrntAxlMinRq_write_IRV, sw-syscond=1}
              WV_VeSCCI_b_FrntAxlTqRqFA_write_IRV: accessed-variable=VeSCCI_b_FrntAxlTqRqFA_write_IRV, variation-point={short-label=vpWV_VeSCCI_b_FrntAxlTqRqFA_write_IRV, sw-syscond=1}
              WV_VeSCCR_b_Output_Torque_LimitFA_write_IRV: accessed-variable=VeSCCR_b_Output_Torque_LimitFA_write_IRV
              WV_VeSCCI_b_RrAxlMaxRqFA_write_IRV: accessed-variable=VeSCCI_b_RrAxlMaxRqFA_write_IRV
              WV_VeSCCI_b_RrAxlMaxRq_write_IRV: accessed-variable=VeSCCI_b_RrAxlMaxRq_write_IRV, variation-point={short-label=vpWV_VeSCCI_b_RrAxlMaxRq_write_IRV, sw-syscond=1}
              WV_VeSCCI_b_RrAxlMinRqFA_write_IRV: accessed-variable=VeSCCI_b_RrAxlMinRqFA_write_IRV
              WV_VeSCCI_b_RrAxlMinRq_write_IRV: accessed-variable=VeSCCI_b_RrAxlMinRq_write_IRV, variation-point={short-label=vpWV_VeSCCI_b_RrAxlMinRq_write_IRV, sw-syscond=1}
              WV_VeSCCI_b_RrAxlTqRqFA_write_IRV: accessed-variable=VeSCCI_b_RrAxlTqRqFA_write_IRV, variation-point={short-label=vpWV_VeSCCI_b_RrAxlTqRqFA_write_IRV, sw-syscond=1}
              WV_VeSCCI_e_EPBHoldSts_write_IRV: accessed-variable=VeSCCI_e_EPBHoldSts_write_IRV, variation-point={short-label=vpWV_VeSCCI_e_EPBHoldSts_write_IRV, sw-syscond=1}
              WV_VeSCCR_M_FrntAxlMax_CL_write_IRV: accessed-variable=VeSCCR_M_FrntAxlMax_CL_write_IRV
              WV_VeSCCR_M_FrntAxlMin_CL_write_IRV: accessed-variable=VeSCCR_M_FrntAxlMin_CL_write_IRV
              WV_VeSCCR_M_RrAxlMax_CL_write_IRV: accessed-variable=VeSCCR_M_RrAxlMax_CL_write_IRV
              WV_VeSCCR_M_RrAxlMin_CL_write_IRV: accessed-variable=VeSCCR_M_RrAxlMin_CL_write_IRV
              WV_VeSCCR_b_AWDDiscnctAllwd_write_IRV: accessed-variable=VeSCCR_b_AWDDiscnctAllwd_write_IRV
              WV_VeSCCR_b_DsblAEMDPGainFrnt_write_IRV: accessed-variable=VeSCCR_b_DsblAEMDPGainFrnt_write_IRV
              WV_VeSCCR_b_DsblAEMDPGainRr_write_IRV: accessed-variable=VeSCCR_b_DsblAEMDPGainRr_write_IRV
              WV_VeSCCR_b_FlyWMaxRq_FA_write_IRV: accessed-variable=VeSCCR_b_FlyWMaxRq_FA_write_IRV, variation-point={short-label=vpWV_VeSCCR_b_FlyWMaxRq_FA_write_IRV, sw-syscond=1}
              WV_VeSCCR_b_FlyWMaxRq_write_IRV: accessed-variable=VeSCCR_b_FlyWMaxRq_write_IRV, variation-point={short-label=vpWV_VeSCCR_b_FlyWMaxRq_write_IRV, sw-syscond=1}
              WV_VeSCCR_b_FlyWMinRq_FA_write_IRV: accessed-variable=VeSCCR_b_FlyWMinRq_FA_write_IRV, variation-point={short-label=vpWV_VeSCCR_b_FlyWMinRq_FA_write_IRV, sw-syscond=1}
              WV_VeSCCR_b_FlyWMinRq_write_IRV: accessed-variable=VeSCCR_b_FlyWMinRq_write_IRV, variation-point={short-label=vpWV_VeSCCR_b_FlyWMinRq_write_IRV, sw-syscond=1}
              WV_VeSCCR_b_FlyWRq_FA_write_IRV: accessed-variable=VeSCCR_b_FlyWRq_FA_write_IRV, variation-point={short-label=vpWV_VeSCCR_b_FlyWRq_FA_write_IRV, sw-syscond=1}
              WV_VeSCCR_b_FrontDFOffReq_write_IRV: accessed-variable=VeSCCR_b_FrontDFOffReq_write_IRV
              WV_VeSCCR_b_RearDFOffReq_write_IRV: accessed-variable=VeSCCR_b_RearDFOffReq_write_IRV
        SCCR_FastTEF1: variation-point={short-label=vpSCCR_FastTEF1, sw-syscond=1}
          data-receive-point-by-arguments:
            45 x access:
              IN_VeATRR_M_OutputTorqReqImmedHTDR_Value: accessed-variable=VeATRR_M_OutputTorqReqImmedHTDR.Value, variation-point={short-label=vpIN_VeATRR_M_OutputTorqReqImmedHTDR_Value, sw-syscond=1}
              IN_VeAXLR_M_OutTorqReqModHH_Axle_Value: accessed-variable=VeAXLR_M_OutTorqReqModHH_Axle.Value, variation-point={short-label=vpIN_VeAXLR_M_OutTorqReqModHH_Axle_Value, sw-syscond=1}
              IN_VeCSVR_b_CanSigVehSpd_FA_Value: accessed-variable=VeCSVR_b_CanSigVehSpd_FA.Value, variation-point={short-label=vpIN_VeCSVR_b_CanSigVehSpd_FA_Value, sw-syscond=1}
              IN_VeCSVR_b_WhlSpdLHF_FA_Value: accessed-variable=VeCSVR_b_WhlSpdLHF_FA.Value, variation-point={short-label=vpIN_VeCSVR_b_WhlSpdLHF_FA_Value, sw-syscond=1}
              IN_VeCSVR_b_WhlSpdLHR_FA_Value: accessed-variable=VeCSVR_b_WhlSpdLHR_FA.Value, variation-point={short-label=vpIN_VeCSVR_b_WhlSpdLHR_FA_Value, sw-syscond=1}
              IN_VeCSVR_b_WhlSpdRHF_FA_Value: accessed-variable=VeCSVR_b_WhlSpdRHF_FA.Value, variation-point={short-label=vpIN_VeCSVR_b_WhlSpdRHF_FA_Value, sw-syscond=1}
              IN_VeCSVR_b_WhlSpdRHR_FA_Value: accessed-variable=VeCSVR_b_WhlSpdRHR_FA.Value, variation-point={short-label=vpIN_VeCSVR_b_WhlSpdRHR_FA_Value, sw-syscond=1}
              IN_VeCSVR_n_WhlSpdLHF_Value: accessed-variable=VeCSVR_n_WhlSpdLHF.Value, variation-point={short-label=vpIN_VeCSVR_n_WhlSpdLHF_Value, sw-syscond=1}
              IN_VeCSVR_n_WhlSpdLHR_Value: accessed-variable=VeCSVR_n_WhlSpdLHR.Value, variation-point={short-label=vpIN_VeCSVR_n_WhlSpdLHR_Value, sw-syscond=1}
              IN_VeCSVR_n_WhlSpdRHF_Value: accessed-variable=VeCSVR_n_WhlSpdRHF.Value, variation-point={short-label=vpIN_VeCSVR_n_WhlSpdRHF_Value, sw-syscond=1}
              IN_VeCSVR_n_WhlSpdRHR_Value: accessed-variable=VeCSVR_n_WhlSpdRHR.Value, variation-point={short-label=vpIN_VeCSVR_n_WhlSpdRHR_Value, sw-syscond=1}
              IN_VeCSVR_v_CanSigVehSpd_Value: accessed-variable=VeCSVR_v_CanSigVehSpd.Value, variation-point={short-label=vpIN_VeCSVR_v_CanSigVehSpd_Value, sw-syscond=1}
              IN_VeFWDR_M_FricTrqClutch_Value: accessed-variable=VeFWDR_M_FricTrqClutch.Value, variation-point={short-label=vpIN_VeFWDR_M_FricTrqClutch_Value, sw-syscond=1}
              IN_VeLLDR_M_FrntAxlAdhMax_Value: accessed-variable=VeLLDR_M_FrntAxlAdhMax.Value, variation-point={short-label=vpIN_VeLLDR_M_FrntAxlAdhMax_Value, sw-syscond=1}
              IN_VeLLDR_M_FrntAxlAdhMin_Value: accessed-variable=VeLLDR_M_FrntAxlAdhMin.Value, variation-point={short-label=vpIN_VeLLDR_M_FrntAxlAdhMin_Value, sw-syscond=1}
              IN_VeLLDR_M_FrntAxlEffMax_Value: accessed-variable=VeLLDR_M_FrntAxlEffMax.Value, variation-point={short-label=vpIN_VeLLDR_M_FrntAxlEffMax_Value, sw-syscond=1}
              IN_VeLLDR_M_FrntAxlEffMin_Value: accessed-variable=VeLLDR_M_FrntAxlEffMin.Value, variation-point={short-label=vpIN_VeLLDR_M_FrntAxlEffMin_Value, sw-syscond=1}
              IN_VeLLDR_M_FrntAxlMax_OL_Value: accessed-variable=VeLLDR_M_FrntAxlMax_OL.Value, variation-point={short-label=vpIN_VeLLDR_M_FrntAxlMax_OL_Value, sw-syscond=1}
              IN_VeLLDR_M_FrntAxlMin_OL_Value: accessed-variable=VeLLDR_M_FrntAxlMin_OL.Value, variation-point={short-label=vpIN_VeLLDR_M_FrntAxlMin_OL_Value, sw-syscond=1}
              IN_VeLLDR_M_FrntAxlStrtgcMax_OL_Value: accessed-variable=VeLLDR_M_FrntAxlStrtgcMax_OL.Value, variation-point={short-label=vpIN_VeLLDR_M_FrntAxlStrtgcMax_OL_Value, sw-syscond=1}
              IN_VeLLDR_M_FrntAxlStrtgcMin_OL_Value: accessed-variable=VeLLDR_M_FrntAxlStrtgcMin_OL.Value, variation-point={short-label=vpIN_VeLLDR_M_FrntAxlStrtgcMin_OL_Value, sw-syscond=1}
              IN_VeLLDR_M_FrntAxlTactFastMax_OL_Value: accessed-variable=VeLLDR_M_FrntAxlTactFastMax_OL.Value, variation-point={short-label=vpIN_VeLLDR_M_FrntAxlTactFastMax_OL_Value, sw-syscond=1}
              IN_VeLLDR_M_FrntAxlTactFastMin_OL_Value: accessed-variable=VeLLDR_M_FrntAxlTactFastMin_OL.Value, variation-point={short-label=vpIN_VeLLDR_M_FrntAxlTactFastMin_OL_Value, sw-syscond=1}
              IN_VeLLDR_M_FrntAxlTactSlowMax_OL_Value: accessed-variable=VeLLDR_M_FrntAxlTactSlowMax_OL.Value, variation-point={short-label=vpIN_VeLLDR_M_FrntAxlTactSlowMax_OL_Value, sw-syscond=1}
              IN_VeLLDR_M_FrntAxlTactSlowMin_OL_Value: accessed-variable=VeLLDR_M_FrntAxlTactSlowMin_OL.Value, variation-point={short-label=vpIN_VeLLDR_M_FrntAxlTactSlowMin_OL_Value, sw-syscond=1}
              IN_VeLLDR_M_RrAxlAdhMax_Value: accessed-variable=VeLLDR_M_RrAxlAdhMax.Value, variation-point={short-label=vpIN_VeLLDR_M_RrAxlAdhMax_Value, sw-syscond=1}
              IN_VeLLDR_M_RrAxlAdhMin_Value: accessed-variable=VeLLDR_M_RrAxlAdhMin.Value, variation-point={short-label=vpIN_VeLLDR_M_RrAxlAdhMin_Value, sw-syscond=1}
              IN_VeLLDR_M_RrAxlEffMax_Value: accessed-variable=VeLLDR_M_RrAxlEffMax.Value, variation-point={short-label=vpIN_VeLLDR_M_RrAxlEffMax_Value, sw-syscond=1}
              IN_VeLLDR_M_RrAxlEffMin_Value: accessed-variable=VeLLDR_M_RrAxlEffMin.Value, variation-point={short-label=vpIN_VeLLDR_M_RrAxlEffMin_Value, sw-syscond=1}
              IN_VeLLDR_M_RrAxlMax_OL_Value: accessed-variable=VeLLDR_M_RrAxlMax_OL.Value, variation-point={short-label=vpIN_VeLLDR_M_RrAxlMax_OL_Value, sw-syscond=1}
              IN_VeLLDR_M_RrAxlMin_OL_Value: accessed-variable=VeLLDR_M_RrAxlMin_OL.Value, variation-point={short-label=vpIN_VeLLDR_M_RrAxlMin_OL_Value, sw-syscond=1}
              IN_VeLLDR_M_RrAxlStrtgcMax_OL_Value: accessed-variable=VeLLDR_M_RrAxlStrtgcMax_OL.Value, variation-point={short-label=vpIN_VeLLDR_M_RrAxlStrtgcMax_OL_Value, sw-syscond=1}
              IN_VeLLDR_M_RrAxlStrtgcMin_OL_Value: accessed-variable=VeLLDR_M_RrAxlStrtgcMin_OL.Value, variation-point={short-label=vpIN_VeLLDR_M_RrAxlStrtgcMin_OL_Value, sw-syscond=1}
              IN_VeLLDR_M_RrAxlTactFastMax_OL_Value: accessed-variable=VeLLDR_M_RrAxlTactFastMax_OL.Value, variation-point={short-label=vpIN_VeLLDR_M_RrAxlTactFastMax_OL_Value, sw-syscond=1}
              IN_VeLLDR_M_RrAxlTactFastMin_OL_Value: accessed-variable=VeLLDR_M_RrAxlTactFastMin_OL.Value, variation-point={short-label=vpIN_VeLLDR_M_RrAxlTactFastMin_OL_Value, sw-syscond=1}
              IN_VeLLDR_M_RrAxlTactSlowMax_OL_Value: accessed-variable=VeLLDR_M_RrAxlTactSlowMax_OL.Value, variation-point={short-label=vpIN_VeLLDR_M_RrAxlTactSlowMax_OL_Value, sw-syscond=1}
              IN_VeLLDR_M_RrAxlTactSlowMin_OL_Value: accessed-variable=VeLLDR_M_RrAxlTactSlowMin_OL.Value, variation-point={short-label=vpIN_VeLLDR_M_RrAxlTactSlowMin_OL_Value, sw-syscond=1}
              IN_VeLLDR_b_PerfAWDFlag_Value: accessed-variable=VeLLDR_b_PerfAWDFlag.Value, variation-point={short-label=vpIN_VeLLDR_b_PerfAWDFlag_Value, sw-syscond=1}
              IN_VeLLDR_b_ZeroTrqAllwd_Value: accessed-variable=VeLLDR_b_ZeroTrqAllwd.Value, variation-point={short-label=vpIN_VeLLDR_b_ZeroTrqAllwd_Value, sw-syscond=1}
              IN_VeLLDR_r_RipAWD_Value: accessed-variable=VeLLDR_r_RipAWD.Value, variation-point={short-label=vpIN_VeLLDR_r_RipAWD_Value, sw-syscond=1}
              IN_VeLLDR_r_RipRegen_Value: accessed-variable=VeLLDR_r_RipRegen.Value, variation-point={short-label=vpIN_VeLLDR_r_RipRegen_Value, sw-syscond=1}
              IN_VePLTR_e_EPBHoldSts_Value: accessed-variable=VePLTR_e_EPBHoldSts.Value, variation-point={short-label=vpIN_VePLTR_e_EPBHoldSts_Value, sw-syscond=1}
              IN_VePLTR_phi_LwsAngle_Value: accessed-variable=VePLTR_phi_LwsAngle.Value, variation-point={short-label=vpIN_VePLTR_phi_LwsAngle_Value, sw-syscond=1}
              IN_VeSRAR_e_LoCHCP_BSM_CANC_Value: accessed-variable=VeSRAR_e_LoCHCP_BSM_CANC.Value, variation-point={short-label=vpIN_VeSRAR_e_LoCHCP_BSM_CANC_Value, sw-syscond=1}
              IN_VeVSDR_n_PrimNoSgndFltrd_Value: accessed-variable=VeVSDR_n_PrimNoSgndFltrd.Value, variation-point={short-label=vpIN_VeVSDR_n_PrimNoSgndFltrd_Value, sw-syscond=1}
          data-send-points:
            60 x access:
              OUT_VeSCCR_b_FrntAxlMaxRqFA_Value: accessed-variable=VeSCCR_b_FrntAxlMaxRqFA.Value
              OUT_VeSCCR_b_RrAxlMinRqFA_Value: accessed-variable=VeSCCR_b_RrAxlMinRqFA.Value
              OUT_VeSCCR_b_FrntAxlMinRqFA_Value: accessed-variable=VeSCCR_b_FrntAxlMinRqFA.Value
              OUT_VeSCCR_b_ZeroTrqAllwd_Value: accessed-variable=VeSCCR_b_ZeroTrqAllwd.Value
              OUT_VeSCCR_b_AWDDiscnctAllwd_Value: accessed-variable=VeSCCR_b_AWDDiscnctAllwd.Value
              OUT_VeSCCR_M_FrntAxlOLMax_Value: accessed-variable=VeSCCR_M_FrntAxlOLMax.Value
              OUT_VeSCCR_M_FrntAxlOLMin_Value: accessed-variable=VeSCCR_M_FrntAxlOLMin.Value
              OUT_VeSCCR_M_RrAxlOLMax_Value: accessed-variable=VeSCCR_M_RrAxlOLMax.Value
              OUT_VeSCCR_M_RrAxlOLMin_Value: accessed-variable=VeSCCR_M_RrAxlOLMin.Value
              OUT_VeSCCR_M_FrntAxlCLMax_Value: accessed-variable=VeSCCR_M_FrntAxlCLMax.Value
              OUT_VeSCCR_M_FrntAxlCLMin_Value: accessed-variable=VeSCCR_M_FrntAxlCLMin.Value
              OUT_VeSCCR_M_RrAxlCLMax_Value: accessed-variable=VeSCCR_M_RrAxlCLMax.Value
              OUT_VeSCCR_M_RrAxlCLMin_Value: accessed-variable=VeSCCR_M_RrAxlCLMin.Value
              OUT_VeSCCR_r_RipAWD_Value: accessed-variable=VeSCCR_r_RipAWD.Value
              OUT_VeSCCR_r_RipRegen_Value: accessed-variable=VeSCCR_r_RipRegen.Value
              OUT_VeSCCR_b_PerfAWDFlag_Value: accessed-variable=VeSCCR_b_PerfAWDFlag.Value
              OUT_VeSCCR_M_FrntAxlStrtgcMax_OL_Value: accessed-variable=VeSCCR_M_FrntAxlStrtgcMax_OL.Value
              OUT_VeSCCR_M_RrAxlStrtgcMax_OL_Value: accessed-variable=VeSCCR_M_RrAxlStrtgcMax_OL.Value
              OUT_VeSCCR_M_FrntAxlStrtgcMin_OL_Value: accessed-variable=VeSCCR_M_FrntAxlStrtgcMin_OL.Value
              OUT_VeSCCR_M_RrAxlStrtgcMin_OL_Value: accessed-variable=VeSCCR_M_RrAxlStrtgcMin_OL.Value
              OUT_VeSCCR_M_FrntAxlTactFastMax_OL_Value: accessed-variable=VeSCCR_M_FrntAxlTactFastMax_OL.Value
              OUT_VeSCCR_M_RrAxlTactFastMax_OL_Value: accessed-variable=VeSCCR_M_RrAxlTactFastMax_OL.Value
              OUT_VeSCCR_M_FrntAxlTactFastMin_OL_Value: accessed-variable=VeSCCR_M_FrntAxlTactFastMin_OL.Value
              OUT_VeSCCR_M_RrAxlTactFastMin_OL_Value: accessed-variable=VeSCCR_M_RrAxlTactFastMin_OL.Value
              OUT_VeSCCR_M_FrntAxlTactSlowMax_OL_Value: accessed-variable=VeSCCR_M_FrntAxlTactSlowMax_OL.Value
              OUT_VeSCCR_M_RrAxlTactSlowMax_OL_Value: accessed-variable=VeSCCR_M_RrAxlTactSlowMax_OL.Value
              OUT_VeSCCR_M_FrntAxlTactSlowMin_OL_Value: accessed-variable=VeSCCR_M_FrntAxlTactSlowMin_OL.Value
              OUT_VeSCCR_M_RrAxlTactSlowMin_OL_Value: accessed-variable=VeSCCR_M_RrAxlTactSlowMin_OL.Value
              OUT_VeSCCR_M_FrntAxlAdhMax_Value: accessed-variable=VeSCCR_M_FrntAxlAdhMax.Value
              OUT_VeSCCR_M_RrAxlAdhMax_Value: accessed-variable=VeSCCR_M_RrAxlAdhMax.Value
              OUT_VeSCCR_M_FrntAxlAdhMin_Value: accessed-variable=VeSCCR_M_FrntAxlAdhMin.Value
              OUT_VeSCCR_M_RrAxlAdhMin_Value: accessed-variable=VeSCCR_M_RrAxlAdhMin.Value
              OUT_VeSCCR_M_FrntAxlEffMax_Value: accessed-variable=VeSCCR_M_FrntAxlEffMax.Value
              OUT_VeSCCR_M_RrAxlEffMax_Value: accessed-variable=VeSCCR_M_RrAxlEffMax.Value
              OUT_VeSCCR_M_FrntAxlEffMin_Value: accessed-variable=VeSCCR_M_FrntAxlEffMin.Value
              OUT_VeSCCR_M_RrAxlEffMin_Value: accessed-variable=VeSCCR_M_RrAxlEffMin.Value
              OUT_VeSCCR_b_FrontDFOffReq_Value: accessed-variable=VeSCCR_b_FrontDFOffReq.Value
              OUT_VeSCCR_b_RearDFOffReq_Value: accessed-variable=VeSCCR_b_RearDFOffReq.Value
              OUT_VeSCCR_b_RrAxlMaxRqFA_Value: accessed-variable=VeSCCR_b_RrAxlMaxRqFA.Value
              OUT_VeSCCR_M_FrntAxlMaxRqPrtctd_Value: accessed-variable=VeSCCR_M_FrntAxlMaxRqPrtctd.Value
              OUT_VeSCCR_b_FrntAxlMinRq_Value: accessed-variable=VeSCCR_b_FrntAxlMinRq.Value
              OUT_VeSCCR_b_RrAxlMinRq_Value: accessed-variable=VeSCCR_b_RrAxlMinRq.Value
              OUT_VeSCCR_b_RrAxlMaxRq_Value: accessed-variable=VeSCCR_b_RrAxlMaxRq.Value
              OUT_VeSCCR_b_FrntAxlRqFA_Value: accessed-variable=VeSCCR_b_FrntAxlRqFA.Value
              OUT_VeSCCR_b_RrAxlRqFA_Value: accessed-variable=VeSCCR_b_RrAxlRqFA.Value
              OUT_VeSCCR_b_FrntAxlRq_Value: accessed-variable=VeSCCR_b_FrntAxlRq.Value
              OUT_VeSCCR_b_RrAxlRq_Value: accessed-variable=VeSCCR_b_RrAxlRq.Value
              OUT_VeSCCR_M_FrntAxlMinRqPrtctd_Value: accessed-variable=VeSCCR_M_FrntAxlMinRqPrtctd.Value
              OUT_VeSCCR_M_FrntAxlMaxRq_Value: accessed-variable=VeSCCR_M_FrntAxlMaxRq.Value
              OUT_VeSCCR_M_FrntAxlMinRq_Value: accessed-variable=VeSCCR_M_FrntAxlMinRq.Value
              OUT_VeSCCR_M_RrAxlMaxRq_Value: accessed-variable=VeSCCR_M_RrAxlMaxRq.Value
              OUT_VeSCCR_M_RrAxlMinRq_Value: accessed-variable=VeSCCR_M_RrAxlMinRq.Value
              OUT_VeSCCR_b_FrntAxlMaxRq_Value: accessed-variable=VeSCCR_b_FrntAxlMaxRq.Value
              OUT_VeSCCR_M_OutputTorqueLimit_Value: accessed-variable=VeSCCR_M_OutputTorqueLimit.Value
              OUT_VeSCCR_b_OutputTorqueLimit_CAN_FA_Value: accessed-variable=VeSCCR_b_OutputTorqueLimit_CAN_FA.Value, variation-point={short-label=vpOUT_VeSCCR_b_OutputTorqueLimit_CAN_FA_Value, sw-syscond=1}
              OUT_VeSCCR_b_Rq_ESCSumFA_Value: accessed-variable=VeSCCR_b_Rq_ESCSumFA.Value
              OUT_VeSCCR_b_Rq_ESCSum_Value: accessed-variable=VeSCCR_b_Rq_ESCSum.Value
              OUT_VeSCCR_M_ESCSumMin_Value: accessed-variable=VeSCCR_M_ESCSumMin.Value
              OUT_VeSCCR_M_ESCSumMax_Value: accessed-variable=VeSCCR_M_ESCSumMax.Value
              OUT_VeSCCR_b_ESCTrqEnblRq_Allowed_Value: accessed-variable=VeSCCR_b_ESCTrqEnblRq_Allowed.Value
          read-local-variables:
            52 x access:
              RV_VeSCCI_M_FrntAxlCLMax_write_IRV: accessed-variable=VeSCCI_M_FrntAxlCLMax_write_IRV, variation-point={short-label=vpRV_VeSCCI_M_FrntAxlCLMax_write_IRV, sw-syscond=1}
              RV_VeSCCI_M_FrntAxlCLMin_write_IRV: accessed-variable=VeSCCI_M_FrntAxlCLMin_write_IRV, variation-point={short-label=vpRV_VeSCCI_M_FrntAxlCLMin_write_IRV, sw-syscond=1}
              RV_VeSCCI_M_FrntAxlOLMax_write_IRV: accessed-variable=VeSCCI_M_FrntAxlOLMax_write_IRV, variation-point={short-label=vpRV_VeSCCI_M_FrntAxlOLMax_write_IRV, sw-syscond=1}
              RV_VeSCCI_M_FrntAxlOLMin_write_IRV: accessed-variable=VeSCCI_M_FrntAxlOLMin_write_IRV, variation-point={short-label=vpRV_VeSCCI_M_FrntAxlOLMin_write_IRV, sw-syscond=1}
              RV_VeSCCI_M_FrntAxlRq_write_IRV: accessed-variable=VeSCCI_M_FrntAxlRq_write_IRV, variation-point={short-label=vpRV_VeSCCI_M_FrntAxlRq_write_IRV, sw-syscond=1}
              RV_VeSCCI_M_FrntAxlTrqEst_write_IRV: accessed-variable=VeSCCI_M_FrntAxlTrqEst_write_IRV, variation-point={short-label=vpRV_VeSCCI_M_FrntAxlTrqEst_write_IRV, sw-syscond=1}
              RV_VeSCCI_M_RrAxlCLMax_write_IRV: accessed-variable=VeSCCI_M_RrAxlCLMax_write_IRV, variation-point={short-label=vpRV_VeSCCI_M_RrAxlCLMax_write_IRV, sw-syscond=1}
              RV_VeSCCI_M_RrAxlCLMin_write_IRV: accessed-variable=VeSCCI_M_RrAxlCLMin_write_IRV, variation-point={short-label=vpRV_VeSCCI_M_RrAxlCLMin_write_IRV, sw-syscond=1}
              RV_VeSCCI_M_RrAxlOLMax_write_IRV: accessed-variable=VeSCCI_M_RrAxlOLMax_write_IRV, variation-point={short-label=vpRV_VeSCCI_M_RrAxlOLMax_write_IRV, sw-syscond=1}
              RV_VeSCCI_M_RrAxlOLMin_write_IRV: accessed-variable=VeSCCI_M_RrAxlOLMin_write_IRV, variation-point={short-label=vpRV_VeSCCI_M_RrAxlOLMin_write_IRV, sw-syscond=1}
              RV_VeSCCI_M_RrAxlRq_write_IRV: accessed-variable=VeSCCI_M_RrAxlRq_write_IRV, variation-point={short-label=vpRV_VeSCCI_M_RrAxlRq_write_IRV, sw-syscond=1}
              RV_VeSCCI_M_RrAxlTrqEst_write_IRV: accessed-variable=VeSCCI_M_RrAxlTrqEst_write_IRV, variation-point={short-label=vpRV_VeSCCI_M_RrAxlTrqEst_write_IRV, sw-syscond=1}
              RV_VeSCCI_b_FrntAxlMaxRqFA_write_IRV: accessed-variable=VeSCCI_b_FrntAxlMaxRqFA_write_IRV, variation-point={short-label=vpRV_VeSCCI_b_FrntAxlMaxRqFA_write_IRV, sw-syscond=1}
              RV_VeSCCI_b_FrntAxlMaxRq_write_IRV: accessed-variable=VeSCCI_b_FrntAxlMaxRq_write_IRV, variation-point={short-label=vpRV_VeSCCI_b_FrntAxlMaxRq_write_IRV, sw-syscond=1}
              RV_VeSCCI_b_FrntAxlMinRqFA_write_IRV: accessed-variable=VeSCCI_b_FrntAxlMinRqFA_write_IRV, variation-point={short-label=vpRV_VeSCCI_b_FrntAxlMinRqFA_write_IRV, sw-syscond=1}
              RV_VeSCCI_b_FrntAxlMinRq_write_IRV: accessed-variable=VeSCCI_b_FrntAxlMinRq_write_IRV, variation-point={short-label=vpRV_VeSCCI_b_FrntAxlMinRq_write_IRV, sw-syscond=1}
              RV_VeSCCI_b_FrntAxlTqRqFA_write_IRV: accessed-variable=VeSCCI_b_FrntAxlTqRqFA_write_IRV, variation-point={short-label=vpRV_VeSCCI_b_FrntAxlTqRqFA_write_IRV, sw-syscond=1}
              RV_VeSCCI_b_RrAxlMaxRqFA_write_IRV: accessed-variable=VeSCCI_b_RrAxlMaxRqFA_write_IRV, variation-point={short-label=vpRV_VeSCCI_b_RrAxlMaxRqFA_write_IRV, sw-syscond=1}
              RV_VeSCCI_b_RrAxlMaxRq_write_IRV: accessed-variable=VeSCCI_b_RrAxlMaxRq_write_IRV, variation-point={short-label=vpRV_VeSCCI_b_RrAxlMaxRq_write_IRV, sw-syscond=1}
              RV_VeSCCI_b_RrAxlMinRqFA_write_IRV: accessed-variable=VeSCCI_b_RrAxlMinRqFA_write_IRV, variation-point={short-label=vpRV_VeSCCI_b_RrAxlMinRqFA_write_IRV, sw-syscond=1}
              RV_VeSCCI_b_RrAxlMinRq_write_IRV: accessed-variable=VeSCCI_b_RrAxlMinRq_write_IRV, variation-point={short-label=vpRV_VeSCCI_b_RrAxlMinRq_write_IRV, sw-syscond=1}
              RV_VeSCCI_b_RrAxlTqRqFA_write_IRV: accessed-variable=VeSCCI_b_RrAxlTqRqFA_write_IRV, variation-point={short-label=vpRV_VeSCCI_b_RrAxlTqRqFA_write_IRV, sw-syscond=1}
              RV_VeSCCI_e_EPBHoldSts_write_IRV: accessed-variable=VeSCCI_e_EPBHoldSts_write_IRV, variation-point={short-label=vpRV_VeSCCI_e_EPBHoldSts_write_IRV, sw-syscond=1}
              RV_VeSCCR_M_FlyWRq_write_IRV: accessed-variable=VeSCCR_M_FlyWRq_write_IRV, variation-point={short-label=vpRV_VeSCCR_M_FlyWRq_write_IRV, sw-syscond=1}
              RV_VeSCCR_M_FrntAxlMax_CL_write_IRV: accessed-variable=VeSCCR_M_FrntAxlMax_CL_write_IRV, variation-point={short-label=vpRV_VeSCCR_M_FrntAxlMax_CL_write_IRV, sw-syscond=1}
              RV_VeSCCR_M_FrntAxlMin_CL_write_IRV: accessed-variable=VeSCCR_M_FrntAxlMin_CL_write_IRV, variation-point={short-label=vpRV_VeSCCR_M_FrntAxlMin_CL_write_IRV, sw-syscond=1}
              RV_VeSCCR_M_FrntAxlRq_write_IRV: accessed-variable=VeSCCR_M_FrntAxlRq_write_IRV, variation-point={short-label=vpRV_VeSCCR_M_FrntAxlRq_write_IRV, sw-syscond=1}
              RV_VeSCCR_M_Output_Torque_Limit_write_IRV: accessed-variable=VeSCCR_M_Output_Torque_Limit_write_IRV, variation-point={short-label=vpRV_VeSCCR_M_Output_Torque_Limit_write_IRV, sw-syscond=1}
              RV_VeSCCR_M_RrAxlMax_CL_write_IRV: accessed-variable=VeSCCR_M_RrAxlMax_CL_write_IRV, variation-point={short-label=vpRV_VeSCCR_M_RrAxlMax_CL_write_IRV, sw-syscond=1}
              RV_VeSCCR_M_RrAxlMin_CL_write_IRV: accessed-variable=VeSCCR_M_RrAxlMin_CL_write_IRV, variation-point={short-label=vpRV_VeSCCR_M_RrAxlMin_CL_write_IRV, sw-syscond=1}
              RV_VeSCCR_M_RrAxlRq_write_IRV: accessed-variable=VeSCCR_M_RrAxlRq_write_IRV, variation-point={short-label=vpRV_VeSCCR_M_RrAxlRq_write_IRV, sw-syscond=1}
              RV_VeSCCR_b_AWDDiscnctAllwd_write_IRV: accessed-variable=VeSCCR_b_AWDDiscnctAllwd_write_IRV, variation-point={short-label=vpRV_VeSCCR_b_AWDDiscnctAllwd_write_IRV, sw-syscond=1}
              RV_VeSCCR_b_DsblAEMDPGainFrnt_write_IRV: accessed-variable=VeSCCR_b_DsblAEMDPGainFrnt_write_IRV, variation-point={short-label=vpRV_VeSCCR_b_DsblAEMDPGainFrnt_write_IRV, sw-syscond=1}
              RV_VeSCCR_b_DsblAEMDPGainRr_write_IRV: accessed-variable=VeSCCR_b_DsblAEMDPGainRr_write_IRV, variation-point={short-label=vpRV_VeSCCR_b_DsblAEMDPGainRr_write_IRV, sw-syscond=1}
              RV_VeSCCR_b_FlyWMaxRq_FA_write_IRV: accessed-variable=VeSCCR_b_FlyWMaxRq_FA_write_IRV, variation-point={short-label=vpRV_VeSCCR_b_FlyWMaxRq_FA_write_IRV, sw-syscond=1}
              RV_VeSCCR_b_FlyWMaxRq_write_IRV: accessed-variable=VeSCCR_b_FlyWMaxRq_write_IRV, variation-point={short-label=vpRV_VeSCCR_b_FlyWMaxRq_write_IRV, sw-syscond=1}
              RV_VeSCCR_b_FlyWMinRq_FA_write_IRV: accessed-variable=VeSCCR_b_FlyWMinRq_FA_write_IRV, variation-point={short-label=vpRV_VeSCCR_b_FlyWMinRq_FA_write_IRV, sw-syscond=1}
              RV_VeSCCR_b_FlyWMinRq_write_IRV: accessed-variable=VeSCCR_b_FlyWMinRq_write_IRV, variation-point={short-label=vpRV_VeSCCR_b_FlyWMinRq_write_IRV, sw-syscond=1}
              RV_VeSCCR_b_FlyWRq_FA_write_IRV: accessed-variable=VeSCCR_b_FlyWRq_FA_write_IRV, variation-point={short-label=vpRV_VeSCCR_b_FlyWRq_FA_write_IRV, sw-syscond=1}
              RV_VeSCCR_b_FrntAxlMaxRqFA_write_IRV: accessed-variable=VeSCCR_b_FrntAxlMaxRqFA_write_IRV, variation-point={short-label=vpRV_VeSCCR_b_FrntAxlMaxRqFA_write_IRV, sw-syscond=1}
              RV_VeSCCR_b_FrntAxlMaxRq_write_IRV: accessed-variable=VeSCCR_b_FrntAxlMaxRq_write_IRV, variation-point={short-label=vpRV_VeSCCR_b_FrntAxlMaxRq_write_IRV, sw-syscond=1}
              RV_VeSCCR_b_FrntAxlMinRqFA_write_IRV: accessed-variable=VeSCCR_b_FrntAxlMinRqFA_write_IRV, variation-point={short-label=vpRV_VeSCCR_b_FrntAxlMinRqFA_write_IRV, sw-syscond=1}
              RV_VeSCCR_b_FrntAxlMinRq_write_IRV: accessed-variable=VeSCCR_b_FrntAxlMinRq_write_IRV, variation-point={short-label=vpRV_VeSCCR_b_FrntAxlMinRq_write_IRV, sw-syscond=1}
              RV_VeSCCR_b_FrntAxlRqFA_write_IRV: accessed-variable=VeSCCR_b_FrntAxlRqFA_write_IRV, variation-point={short-label=vpRV_VeSCCR_b_FrntAxlRqFA_write_IRV, sw-syscond=1}
              RV_VeSCCR_b_FrontDFOffReq_write_IRV: accessed-variable=VeSCCR_b_FrontDFOffReq_write_IRV, variation-point={short-label=vpRV_VeSCCR_b_FrontDFOffReq_write_IRV, sw-syscond=1}
              RV_VeSCCR_b_Output_Torque_LimitFA_write_IRV: accessed-variable=VeSCCR_b_Output_Torque_LimitFA_write_IRV, variation-point={short-label=vpRV_VeSCCR_b_Output_Torque_LimitFA_write_IRV, sw-syscond=1}
              RV_VeSCCR_b_RearDFOffReq_write_IRV: accessed-variable=VeSCCR_b_RearDFOffReq_write_IRV, variation-point={short-label=vpRV_VeSCCR_b_RearDFOffReq_write_IRV, sw-syscond=1}
              RV_VeSCCR_b_RrAxlMaxRqFA_write_IRV: accessed-variable=VeSCCR_b_RrAxlMaxRqFA_write_IRV, variation-point={short-label=vpRV_VeSCCR_b_RrAxlMaxRqFA_write_IRV, sw-syscond=1}
              RV_VeSCCR_b_RrAxlMaxRq_write_IRV: accessed-variable=VeSCCR_b_RrAxlMaxRq_write_IRV, variation-point={short-label=vpRV_VeSCCR_b_RrAxlMaxRq_write_IRV, sw-syscond=1}
              RV_VeSCCR_b_RrAxlMinRqFA_write_IRV: accessed-variable=VeSCCR_b_RrAxlMinRqFA_write_IRV, variation-point={short-label=vpRV_VeSCCR_b_RrAxlMinRqFA_write_IRV, sw-syscond=1}
              RV_VeSCCR_b_RrAxlMinRq_write_IRV: accessed-variable=VeSCCR_b_RrAxlMinRq_write_IRV, variation-point={short-label=vpRV_VeSCCR_b_RrAxlMinRq_write_IRV, sw-syscond=1}
              RV_VeSCCR_b_RrAxlRqFA_write_IRV: accessed-variable=VeSCCR_b_RrAxlRqFA_write_IRV, variation-point={short-label=vpRV_VeSCCR_b_RrAxlRqFA_write_IRV, sw-syscond=1}
          written-local-variables:
            23 x access:
              WV_VeSCCI_M_FrntAxlCLMax_write_IRV: accessed-variable=VeSCCI_M_FrntAxlCLMax_write_IRV, variation-point={short-label=vpWV_VeSCCI_M_FrntAxlCLMax_write_IRV, sw-syscond=1}
              WV_VeSCCI_M_FrntAxlCLMin_write_IRV: accessed-variable=VeSCCI_M_FrntAxlCLMin_write_IRV, variation-point={short-label=vpWV_VeSCCI_M_FrntAxlCLMin_write_IRV, sw-syscond=1}
              WV_VeSCCI_M_FrntAxlOLMax_write_IRV: accessed-variable=VeSCCI_M_FrntAxlOLMax_write_IRV, variation-point={short-label=vpWV_VeSCCI_M_FrntAxlOLMax_write_IRV, sw-syscond=1}
              WV_VeSCCI_M_FrntAxlOLMin_write_IRV: accessed-variable=VeSCCI_M_FrntAxlOLMin_write_IRV, variation-point={short-label=vpWV_VeSCCI_M_FrntAxlOLMin_write_IRV, sw-syscond=1}
              WV_VeSCCI_M_FrntAxlRq_write_IRV: accessed-variable=VeSCCI_M_FrntAxlRq_write_IRV, variation-point={short-label=vpWV_VeSCCI_M_FrntAxlRq_write_IRV, sw-syscond=1}
              WV_VeSCCI_M_RrAxlCLMax_write_IRV: accessed-variable=VeSCCI_M_RrAxlCLMax_write_IRV, variation-point={short-label=vpWV_VeSCCI_M_RrAxlCLMax_write_IRV, sw-syscond=1}
              WV_VeSCCI_M_RrAxlCLMin_write_IRV: accessed-variable=VeSCCI_M_RrAxlCLMin_write_IRV, variation-point={short-label=vpWV_VeSCCI_M_RrAxlCLMin_write_IRV, sw-syscond=1}
              WV_VeSCCI_M_RrAxlOLMax_write_IRV: accessed-variable=VeSCCI_M_RrAxlOLMax_write_IRV, variation-point={short-label=vpWV_VeSCCI_M_RrAxlOLMax_write_IRV, sw-syscond=1}
              WV_VeSCCI_M_RrAxlOLMin_write_IRV: accessed-variable=VeSCCI_M_RrAxlOLMin_write_IRV, variation-point={short-label=vpWV_VeSCCI_M_RrAxlOLMin_write_IRV, sw-syscond=1}
              WV_VeSCCI_M_RrAxlRq_write_IRV: accessed-variable=VeSCCI_M_RrAxlRq_write_IRV, variation-point={short-label=vpWV_VeSCCI_M_RrAxlRq_write_IRV, sw-syscond=1}
              WV_VeSCCI_b_DsblAEMDPGainFrnt_write_IRV: accessed-variable=VeSCCI_b_DsblAEMDPGainFrnt_write_IRV, variation-point={short-label=vpWV_VeSCCI_b_DsblAEMDPGainFrnt_write_IRV, sw-syscond=1}
              WV_VeSCCI_b_DsblAEMDPGainRr_write_IRV: accessed-variable=VeSCCI_b_DsblAEMDPGainRr_write_IRV, variation-point={short-label=vpWV_VeSCCI_b_DsblAEMDPGainRr_write_IRV, sw-syscond=1}
              WV_VeSCCI_b_FrntAxlMaxRqFA_write_IRV: accessed-variable=VeSCCI_b_FrntAxlMaxRqFA_write_IRV, variation-point={short-label=vpWV_VeSCCI_b_FrntAxlMaxRqFA_write_IRV, sw-syscond=1}
              WV_VeSCCI_b_FrntAxlMaxRq_write_IRV: accessed-variable=VeSCCI_b_FrntAxlMaxRq_write_IRV, variation-point={short-label=vpWV_VeSCCI_b_FrntAxlMaxRq_write_IRV, sw-syscond=1}
              WV_VeSCCI_b_FrntAxlMinRqFA_write_IRV: accessed-variable=VeSCCI_b_FrntAxlMinRqFA_write_IRV, variation-point={short-label=vpWV_VeSCCI_b_FrntAxlMinRqFA_write_IRV, sw-syscond=1}
              WV_VeSCCI_b_FrntAxlMinRq_write_IRV: accessed-variable=VeSCCI_b_FrntAxlMinRq_write_IRV, variation-point={short-label=vpWV_VeSCCI_b_FrntAxlMinRq_write_IRV, sw-syscond=1}
              WV_VeSCCI_b_FrntAxlTqRqFA_write_IRV: accessed-variable=VeSCCI_b_FrntAxlTqRqFA_write_IRV, variation-point={short-label=vpWV_VeSCCI_b_FrntAxlTqRqFA_write_IRV, sw-syscond=1}
              WV_VeSCCI_b_RrAxlMaxRqFA_write_IRV: accessed-variable=VeSCCI_b_RrAxlMaxRqFA_write_IRV, variation-point={short-label=vpWV_VeSCCI_b_RrAxlMaxRqFA_write_IRV, sw-syscond=1}
              WV_VeSCCI_b_RrAxlMaxRq_write_IRV: accessed-variable=VeSCCI_b_RrAxlMaxRq_write_IRV, variation-point={short-label=vpWV_VeSCCI_b_RrAxlMaxRq_write_IRV, sw-syscond=1}
              WV_VeSCCI_b_RrAxlMinRqFA_write_IRV: accessed-variable=VeSCCI_b_RrAxlMinRqFA_write_IRV, variation-point={short-label=vpWV_VeSCCI_b_RrAxlMinRqFA_write_IRV, sw-syscond=1}
              WV_VeSCCI_b_RrAxlMinRq_write_IRV: accessed-variable=VeSCCI_b_RrAxlMinRq_write_IRV, variation-point={short-label=vpWV_VeSCCI_b_RrAxlMinRq_write_IRV, sw-syscond=1}
              WV_VeSCCI_b_RrAxlTqRqFA_write_IRV: accessed-variable=VeSCCI_b_RrAxlTqRqFA_write_IRV, variation-point={short-label=vpWV_VeSCCI_b_RrAxlTqRqFA_write_IRV, sw-syscond=1}
              WV_VeSCCI_e_EPBHoldSts_write_IRV: accessed-variable=VeSCCI_e_EPBHoldSts_write_IRV, variation-point={short-label=vpWV_VeSCCI_e_EPBHoldSts_write_IRV, sw-syscond=1}
        SCCR_FastTEF2: variation-point={short-label=vpSCCR_FastTEF2, sw-syscond=1}
          data-receive-point-by-arguments:
            8 x access:
              IN_VeBTQR_M_DrvrIntndedTotBrkTrq_Value: accessed-variable=VeBTQR_M_DrvrIntndedTotBrkTrq.Value, variation-point={short-label=vpIN_VeBTQR_M_DrvrIntndedTotBrkTrq_Value, sw-syscond=1}
              IN_VeHSER_e_RngSt_Value: accessed-variable=VeHSER_e_RngSt.Value, variation-point={short-label=vpIN_VeHSER_e_RngSt_Value, sw-syscond=1}
              IN_VeHTDR_M_OptToFront_OptTaTb_Value: accessed-variable=VeHTDR_M_OptToFront_OptTaTb.Value, variation-point={short-label=vpIN_VeHTDR_M_OptToFront_OptTaTb_Value, sw-syscond=1}
              IN_VeHTDR_M_OptToRear_OptTaTb_Value: accessed-variable=VeHTDR_M_OptToRear_OptTaTb.Value, variation-point={short-label=vpIN_VeHTDR_M_OptToRear_OptTaTb_Value, sw-syscond=1}
              IN_VeOSMR_b_SeriesModeAllowed_Value: accessed-variable=VeOSMR_b_SeriesModeAllowed.Value, variation-point={short-label=vpIN_VeOSMR_b_SeriesModeAllowed_Value, sw-syscond=1}
              IN_VeTRGR_e_VldtdTransRngSt_Value: accessed-variable=VeTRGR_e_VldtdTransRngSt.Value, variation-point={short-label=vpIN_VeTRGR_e_VldtdTransRngSt_Value, sw-syscond=1}
              IN_VeVSDR_n_PrimNoSgndFltrd_Value: accessed-variable=VeVSDR_n_PrimNoSgndFltrd.Value, variation-point={short-label=vpIN_VeVSDR_n_PrimNoSgndFltrd_Value, sw-syscond=1}
              IN_VeWTAR_r_PRNDL_Coeff_Value: accessed-variable=VeWTAR_r_PRNDL_Coeff.Value, variation-point={short-label=vpIN_VeWTAR_r_PRNDL_Coeff_Value, sw-syscond=1}
          data-send-points:
            access OUT_VeSCCR_M_RrAxlTrqEstRadio_Value: accessed-variable=VeSCCR_M_RrAxlTrqEstRadio.Value
            access OUT_VeSCCR_M_FrntAxlTrqEstRadio_Value: accessed-variable=VeSCCR_M_FrntAxlTrqEstRadio.Value
          read-local-variables:
            access RV_VeSCCI_M_FrntAxlTrqEst_write_IRV: accessed-variable=VeSCCI_M_FrntAxlTrqEst_write_IRV, variation-point={short-label=vpRV_VeSCCI_M_FrntAxlTrqEst_write_IRV, sw-syscond=1}
            access RV_VeSCCI_M_RrAxlTrqEst_write_IRV: accessed-variable=VeSCCI_M_RrAxlTrqEst_write_IRV, variation-point={short-label=vpRV_VeSCCI_M_RrAxlTrqEst_write_IRV, sw-syscond=1}
            access RV_VeSCCI_e_EPBHoldSts_write_IRV: accessed-variable=VeSCCI_e_EPBHoldSts_write_IRV, variation-point={short-label=vpRV_VeSCCI_e_EPBHoldSts_write_IRV, sw-syscond=1}
          written-local-variables:
            access WV_VeSCCI_M_FrntAxlTrqEst_write_IRV: accessed-variable=VeSCCI_M_FrntAxlTrqEst_write_IRV, variation-point={short-label=vpWV_VeSCCI_M_FrntAxlTrqEst_write_IRV, sw-syscond=1}
            access WV_VeSCCI_M_RrAxlTrqEst_write_IRV: accessed-variable=VeSCCI_M_RrAxlTrqEst_write_IRV, variation-point={short-label=vpWV_VeSCCI_M_RrAxlTrqEst_write_IRV, sw-syscond=1}
        FsftSCCR_M_FlyWRq: variation-point={short-label=vpFsftSCCR_M_FlyWRq, sw-syscond=1}
          written-local-variables:
            access WV_VeSCCR_b_FlyWRq_FA_write_IRV: accessed-variable=VeSCCR_b_FlyWRq_FA_write_IRV, variation-point={short-label=vpWV_VeSCCR_b_FlyWRq_FA_write_IRV, sw-syscond=1}
        FsftSCCR_M_FrntAxlRq: variation-point={short-label=vpFsftSCCR_M_FrntAxlRq, sw-syscond=1}
          written-local-variables:
            access WV_VeSCCR_M_FrntAxlRq_write_IRV: accessed-variable=VeSCCR_M_FrntAxlRq_write_IRV, variation-point={short-label=vpWV_VeSCCR_M_FrntAxlRq_write_IRV, sw-syscond=1}
            access WV_VeSCCR_b_FrntAxlRqFA_write_IRV: accessed-variable=VeSCCR_b_FrntAxlRqFA_write_IRV, variation-point={short-label=vpWV_VeSCCR_b_FrntAxlRqFA_write_IRV, sw-syscond=1}
        FsftSCCR_M_Output_Torque_Limit: variation-point={short-label=vpFsftSCCR_M_Output_Torque_Limit, sw-syscond=1}
          written-local-variables:
            access WV_VeSCCR_b_Output_Torque_LimitFA_write_IRV: accessed-variable=VeSCCR_b_Output_Torque_LimitFA_write_IRV, variation-point={short-label=vpWV_VeSCCR_b_Output_Torque_LimitFA_write_IRV, sw-syscond=1}
        FsftSCCR_M_RrAxlRq: variation-point={short-label=vpFsftSCCR_M_RrAxlRq, sw-syscond=1}
          written-local-variables:
            access WV_VeSCCR_M_RrAxlRq_write_IRV: accessed-variable=VeSCCR_M_RrAxlRq_write_IRV, variation-point={short-label=vpWV_VeSCCR_M_RrAxlRq_write_IRV, sw-syscond=1}
            access WV_VeSCCR_b_RrAxlRqFA_write_IRV: accessed-variable=VeSCCR_b_RrAxlRqFA_write_IRV, variation-point={short-label=vpWV_VeSCCR_b_RrAxlRqFA_write_IRV, sw-syscond=1}
        FsftSCCR_b_FlyWMaxRq: variation-point={short-label=vpFsftSCCR_b_FlyWMaxRq, sw-syscond=1}
          written-local-variables:
            access WV_VeSCCR_b_FlyWMaxRq_FA_write_IRV: accessed-variable=VeSCCR_b_FlyWMaxRq_FA_write_IRV, variation-point={short-label=vpWV_VeSCCR_b_FlyWMaxRq_FA_write_IRV, sw-syscond=1}
        FsftSCCR_b_FlyWMinRq: variation-point={short-label=vpFsftSCCR_b_FlyWMinRq, sw-syscond=1}
          written-local-variables:
            access WV_VeSCCR_b_FlyWMinRq_FA_write_IRV: accessed-variable=VeSCCR_b_FlyWMinRq_FA_write_IRV, variation-point={short-label=vpWV_VeSCCR_b_FlyWMinRq_FA_write_IRV, sw-syscond=1}
        FsftSCCR_b_FrntAxlMaxRq: variation-point={short-label=vpFsftSCCR_b_FrntAxlMaxRq, sw-syscond=1}
          written-local-variables:
            access WV_VeSCCR_b_FrntAxlMaxRqFA_write_IRV: accessed-variable=VeSCCR_b_FrntAxlMaxRqFA_write_IRV, variation-point={short-label=vpWV_VeSCCR_b_FrntAxlMaxRqFA_write_IRV, sw-syscond=1}
            access WV_VeSCCR_b_FrntAxlMaxRq_write_IRV: accessed-variable=VeSCCR_b_FrntAxlMaxRq_write_IRV, variation-point={short-label=vpWV_VeSCCR_b_FrntAxlMaxRq_write_IRV, sw-syscond=1}
        FsftSCCR_b_FrntAxlMinRq: variation-point={short-label=vpFsftSCCR_b_FrntAxlMinRq, sw-syscond=1}
          written-local-variables:
            access WV_VeSCCR_b_FrntAxlMinRqFA_write_IRV: accessed-variable=VeSCCR_b_FrntAxlMinRqFA_write_IRV, variation-point={short-label=vpWV_VeSCCR_b_FrntAxlMinRqFA_write_IRV, sw-syscond=1}
            access WV_VeSCCR_b_FrntAxlMinRq_write_IRV: accessed-variable=VeSCCR_b_FrntAxlMinRq_write_IRV, variation-point={short-label=vpWV_VeSCCR_b_FrntAxlMinRq_write_IRV, sw-syscond=1}
        FsftSCCR_b_RrAxlMaxRq: variation-point={short-label=vpFsftSCCR_b_RrAxlMaxRq, sw-syscond=1}
          written-local-variables:
            access WV_VeSCCR_b_RrAxlMaxRqFA_write_IRV: accessed-variable=VeSCCR_b_RrAxlMaxRqFA_write_IRV, variation-point={short-label=vpWV_VeSCCR_b_RrAxlMaxRqFA_write_IRV, sw-syscond=1}
            access WV_VeSCCR_b_RrAxlMaxRq_write_IRV: accessed-variable=VeSCCR_b_RrAxlMaxRq_write_IRV, variation-point={short-label=vpWV_VeSCCR_b_RrAxlMaxRq_write_IRV, sw-syscond=1}
        FsftSCCR_b_RrAxlMinRq: variation-point={short-label=vpFsftSCCR_b_RrAxlMinRq, sw-syscond=1}
          written-local-variables:
            access WV_VeSCCR_b_RrAxlMinRqFA_write_IRV: accessed-variable=VeSCCR_b_RrAxlMinRqFA_write_IRV, variation-point={short-label=vpWV_VeSCCR_b_RrAxlMinRqFA_write_IRV, sw-syscond=1}
            access WV_VeSCCR_b_RrAxlMinRq_write_IRV: accessed-variable=VeSCCR_b_RrAxlMinRq_write_IRV, variation-point={short-label=vpWV_VeSCCR_b_RrAxlMinRq_write_IRV, sw-syscond=1}
        PokeSCCR_M_FlyWRq: variation-point={short-label=vpPokeSCCR_M_FlyWRq, sw-syscond=1}
          written-local-variables:
            access WV_VeSCCR_M_FlyWRq_write_IRV: accessed-variable=VeSCCR_M_FlyWRq_write_IRV, variation-point={short-label=vpWV_VeSCCR_M_FlyWRq_write_IRV, sw-syscond=1}
            access WV_VeSCCR_b_FlyWRq_FA_write_IRV: accessed-variable=VeSCCR_b_FlyWRq_FA_write_IRV, variation-point={short-label=vpWV_VeSCCR_b_FlyWRq_FA_write_IRV, sw-syscond=1}
        PokeSCCR_M_FrntAxlMax_CL: variation-point={short-label=vpPokeSCCR_M_FrntAxlMax_CL, sw-syscond=1}
          written-local-variables:
            access WV_VeSCCR_M_FrntAxlMax_CL_write_IRV: accessed-variable=VeSCCR_M_FrntAxlMax_CL_write_IRV, variation-point={short-label=vpWV_VeSCCR_M_FrntAxlMax_CL_write_IRV, sw-syscond=1}
        PokeSCCR_M_FrntAxlMin_CL: variation-point={short-label=vpPokeSCCR_M_FrntAxlMin_CL, sw-syscond=1}
          written-local-variables:
            access WV_VeSCCR_M_FrntAxlMin_CL_write_IRV: accessed-variable=VeSCCR_M_FrntAxlMin_CL_write_IRV, variation-point={short-label=vpWV_VeSCCR_M_FrntAxlMin_CL_write_IRV, sw-syscond=1}
        PokeSCCR_M_FrntAxlRq: variation-point={short-label=vpPokeSCCR_M_FrntAxlRq, sw-syscond=1}
          written-local-variables:
            access WV_VeSCCR_M_FrntAxlRq_write_IRV: accessed-variable=VeSCCR_M_FrntAxlRq_write_IRV, variation-point={short-label=vpWV_VeSCCR_M_FrntAxlRq_write_IRV, sw-syscond=1}
            access WV_VeSCCR_b_FrntAxlRqFA_write_IRV: accessed-variable=VeSCCR_b_FrntAxlRqFA_write_IRV, variation-point={short-label=vpWV_VeSCCR_b_FrntAxlRqFA_write_IRV, sw-syscond=1}
        PokeSCCR_M_Output_Torque_Limit: variation-point={short-label=vpPokeSCCR_M_Output_Torque_Limit, sw-syscond=1}
          written-local-variables:
            access WV_VeSCCR_M_Output_Torque_Limit_write_IRV: accessed-variable=VeSCCR_M_Output_Torque_Limit_write_IRV, variation-point={short-label=vpWV_VeSCCR_M_Output_Torque_Limit_write_IRV, sw-syscond=1}
            access WV_VeSCCR_b_Output_Torque_LimitFA_write_IRV: accessed-variable=VeSCCR_b_Output_Torque_LimitFA_write_IRV, variation-point={short-label=vpWV_VeSCCR_b_Output_Torque_LimitFA_write_IRV, sw-syscond=1}
        PokeSCCR_M_RrAxlMax_CL: variation-point={short-label=vpPokeSCCR_M_RrAxlMax_CL, sw-syscond=1}
          written-local-variables:
            access WV_VeSCCR_M_RrAxlMax_CL_write_IRV: accessed-variable=VeSCCR_M_RrAxlMax_CL_write_IRV, variation-point={short-label=vpWV_VeSCCR_M_RrAxlMax_CL_write_IRV, sw-syscond=1}
        PokeSCCR_M_RrAxlMin_CL: variation-point={short-label=vpPokeSCCR_M_RrAxlMin_CL, sw-syscond=1}
          written-local-variables:
            access WV_VeSCCR_M_RrAxlMin_CL_write_IRV: accessed-variable=VeSCCR_M_RrAxlMin_CL_write_IRV, variation-point={short-label=vpWV_VeSCCR_M_RrAxlMin_CL_write_IRV, sw-syscond=1}
        PokeSCCR_M_RrAxlRq: variation-point={short-label=vpPokeSCCR_M_RrAxlRq, sw-syscond=1}
          written-local-variables:
            access WV_VeSCCR_M_RrAxlRq_write_IRV: accessed-variable=VeSCCR_M_RrAxlRq_write_IRV, variation-point={short-label=vpWV_VeSCCR_M_RrAxlRq_write_IRV, sw-syscond=1}
            access WV_VeSCCR_b_RrAxlRqFA_write_IRV: accessed-variable=VeSCCR_b_RrAxlRqFA_write_IRV, variation-point={short-label=vpWV_VeSCCR_b_RrAxlRqFA_write_IRV, sw-syscond=1}
        PokeSCCR_b_AWDDiscnctAllwd: variation-point={short-label=vpPokeSCCR_b_AWDDiscnctAllwd, sw-syscond=1}
          written-local-variables:
            access WV_VeSCCR_b_AWDDiscnctAllwd_write_IRV: accessed-variable=VeSCCR_b_AWDDiscnctAllwd_write_IRV, variation-point={short-label=vpWV_VeSCCR_b_AWDDiscnctAllwd_write_IRV, sw-syscond=1}
        PokeSCCR_b_DsblAEMDPGainFrnt: variation-point={short-label=vpPokeSCCR_b_DsblAEMDPGainFrnt, sw-syscond=1}
          written-local-variables:
            access WV_VeSCCR_b_DsblAEMDPGainFrnt_write_IRV: accessed-variable=VeSCCR_b_DsblAEMDPGainFrnt_write_IRV, variation-point={short-label=vpWV_VeSCCR_b_DsblAEMDPGainFrnt_write_IRV, sw-syscond=1}
        PokeSCCR_b_DsblAEMDPGainRr: variation-point={short-label=vpPokeSCCR_b_DsblAEMDPGainRr, sw-syscond=1}
          written-local-variables:
            access WV_VeSCCR_b_DsblAEMDPGainRr_write_IRV: accessed-variable=VeSCCR_b_DsblAEMDPGainRr_write_IRV, variation-point={short-label=vpWV_VeSCCR_b_DsblAEMDPGainRr_write_IRV, sw-syscond=1}
        PokeSCCR_b_FlyWMaxRq: variation-point={short-label=vpPokeSCCR_b_FlyWMaxRq, sw-syscond=1}
          written-local-variables:
            access WV_VeSCCR_b_FlyWMaxRq_FA_write_IRV: accessed-variable=VeSCCR_b_FlyWMaxRq_FA_write_IRV, variation-point={short-label=vpWV_VeSCCR_b_FlyWMaxRq_FA_write_IRV, sw-syscond=1}
            access WV_VeSCCR_b_FlyWMaxRq_write_IRV: accessed-variable=VeSCCR_b_FlyWMaxRq_write_IRV, variation-point={short-label=vpWV_VeSCCR_b_FlyWMaxRq_write_IRV, sw-syscond=1}
        PokeSCCR_b_FlyWMinRq: variation-point={short-label=vpPokeSCCR_b_FlyWMinRq, sw-syscond=1}
          written-local-variables:
            access WV_VeSCCR_b_FlyWMinRq_FA_write_IRV: accessed-variable=VeSCCR_b_FlyWMinRq_FA_write_IRV, variation-point={short-label=vpWV_VeSCCR_b_FlyWMinRq_FA_write_IRV, sw-syscond=1}
            access WV_VeSCCR_b_FlyWMinRq_write_IRV: accessed-variable=VeSCCR_b_FlyWMinRq_write_IRV, variation-point={short-label=vpWV_VeSCCR_b_FlyWMinRq_write_IRV, sw-syscond=1}
        PokeSCCR_b_FrntAxlMaxRq: variation-point={short-label=vpPokeSCCR_b_FrntAxlMaxRq, sw-syscond=1}
          written-local-variables:
            access WV_VeSCCR_b_FrntAxlMaxRqFA_write_IRV: accessed-variable=VeSCCR_b_FrntAxlMaxRqFA_write_IRV, variation-point={short-label=vpWV_VeSCCR_b_FrntAxlMaxRqFA_write_IRV, sw-syscond=1}
            access WV_VeSCCR_b_FrntAxlMaxRq_write_IRV: accessed-variable=VeSCCR_b_FrntAxlMaxRq_write_IRV, variation-point={short-label=vpWV_VeSCCR_b_FrntAxlMaxRq_write_IRV, sw-syscond=1}
        PokeSCCR_b_FrntAxlMinRq: variation-point={short-label=vpPokeSCCR_b_FrntAxlMinRq, sw-syscond=1}
          written-local-variables:
            access WV_VeSCCR_b_FrntAxlMinRqFA_write_IRV: accessed-variable=VeSCCR_b_FrntAxlMinRqFA_write_IRV, variation-point={short-label=vpWV_VeSCCR_b_FrntAxlMinRqFA_write_IRV, sw-syscond=1}
            access WV_VeSCCR_b_FrntAxlMinRq_write_IRV: accessed-variable=VeSCCR_b_FrntAxlMinRq_write_IRV, variation-point={short-label=vpWV_VeSCCR_b_FrntAxlMinRq_write_IRV, sw-syscond=1}
        PokeSCCR_b_FrontDFOffReq: variation-point={short-label=vpPokeSCCR_b_FrontDFOffReq, sw-syscond=1}
          written-local-variables:
            access WV_VeSCCR_b_FrontDFOffReq_write_IRV: accessed-variable=VeSCCR_b_FrontDFOffReq_write_IRV, variation-point={short-label=vpWV_VeSCCR_b_FrontDFOffReq_write_IRV, sw-syscond=1}
        PokeSCCR_b_RearDFOffReq: variation-point={short-label=vpPokeSCCR_b_RearDFOffReq, sw-syscond=1}
          written-local-variables:
            access WV_VeSCCR_b_RearDFOffReq_write_IRV: accessed-variable=VeSCCR_b_RearDFOffReq_write_IRV, variation-point={short-label=vpWV_VeSCCR_b_RearDFOffReq_write_IRV, sw-syscond=1}
        PokeSCCR_b_RrAxlMaxRq: variation-point={short-label=vpPokeSCCR_b_RrAxlMaxRq, sw-syscond=1}
          written-local-variables:
            access WV_VeSCCR_b_RrAxlMaxRqFA_write_IRV: accessed-variable=VeSCCR_b_RrAxlMaxRqFA_write_IRV, variation-point={short-label=vpWV_VeSCCR_b_RrAxlMaxRqFA_write_IRV, sw-syscond=1}
            access WV_VeSCCR_b_RrAxlMaxRq_write_IRV: accessed-variable=VeSCCR_b_RrAxlMaxRq_write_IRV, variation-point={short-label=vpWV_VeSCCR_b_RrAxlMaxRq_write_IRV, sw-syscond=1}
        PokeSCCR_b_RrAxlMinRq: variation-point={short-label=vpPokeSCCR_b_RrAxlMinRq, sw-syscond=1}
          written-local-variables:
            access WV_VeSCCR_b_RrAxlMinRqFA_write_IRV: accessed-variable=VeSCCR_b_RrAxlMinRqFA_write_IRV, variation-point={short-label=vpWV_VeSCCR_b_RrAxlMinRqFA_write_IRV, sw-syscond=1}
            access WV_VeSCCR_b_RrAxlMinRq_write_IRV: accessed-variable=VeSCCR_b_RrAxlMinRq_write_IRV, variation-point={short-label=vpWV_VeSCCR_b_RrAxlMinRq_write_IRV, sw-syscond=1}
      variation point proxy Variant_SCCR_1: category=CONDITION, condition-access=0
      variation point proxy Variant_SCCR_3: category=CONDITION, condition-access=1
